VERSION ""

NS_ :

BS_:

BU_: Tester Charger TEL Display BMS VCU MotorController Front_BPS Rear_BPS Vehicle Tester Charger TEL Display BMS VCU MotorController Front_BPS Rear_BPS Vehicle

VAL_TABLE_ Brightness_Control 10 "100% Brightness" 9 "90% Brightness" 8 "80% Brightness" 7 "70% Brightness" 6 "60% Brightness" 5 "50% Brightness" 4 "40% Brightness" 3 "30% Brightness" 2 "20% Brightness" 1 "10% Brightness" 0 "100% Brightness" ;
VAL_TABLE_ VCU_Charge_Current_Lim_A 7 "FAULT_BIT_READ_SBS_CONFIG" 6 "FAULT_BIT_READ_CALIBRATION" 5 "FAULT_BIT_READ_POWER" 4 "FAULT_BIT_READ_FUEL_GAUGING" 3 "FAULT_BIT_READ_ADV_CHRG_ALGO" 2 "FAULT_BIT_READ_PERM_FAIL" 1 "FAULT_BIT_READ_SETTINGS" 0 "FAULT_BIT_READ_PROTECTION" ;
VAL_TABLE_ Hibernation 2 "Blink" 1 "Enabled" 0 "Disabled" ;
VAL_TABLE_ SpeedMode 3 "Rush" 2 "Ride" 1 "Eco" 0 "Default" ;
VAL_TABLE_ TripStatus 1 "Trip2" 0 "Trip1" ;
VAL_TABLE_ Charger_Status_ERR_NRML 1 "Error" 0 "Normal" ;
VAL_TABLE_ Charger_TX 1 "Disable" 0 "Enable" ;
VAL_TABLE_ Error_State 2 "Permanenet_Fault" 1 "Temporary_Fault" 0 "No Fault" ;
VAL_TABLE_ Kill_SwitchStatus 1 "kill Switch Off" 0 "Kill Switch On" ;
VAL_TABLE_ Switch_statius 1 "Pressed" 0 "Not  Pressed" ;
VAL_TABLE_ Throttle_Control 1 "VCU CAN Command throttle%" 0 "Motor Controller HW Throttle%" ;
VAL_TABLE_ DriveMode_Req 3 "Rush" 2 "Ride" 1 "Eco" 0 "Default" 7 "Reserved" 6 "Reserved" 5 "Reserved" 4 "Reserved" ;
VAL_TABLE_ Deratings 1 "Enabled" 0 "Disabled" ;
VAL_TABLE_ DriveMode_Ack 7 "Reserved" 6 "Reserved" 5 "Reserved" 4 "Reserved" 3 "Rush" 2 "Ride" 1 "Eco" 0 "Reserved" ;
VAL_TABLE_ OCD_Latch 1 "Lacth" 0 "Default" ;
VAL_TABLE_ Load_V_present 1 "DFET On" 0 "DFET Off" ;
VAL_TABLE_ KeyStatus_BMS 1 "Connected_vl" 0 "Not Connected_ep" ;
VAL_TABLE_ DFET_Status 1 "MDFET_ON" 0 "MDFET_OFF" ;
VAL_TABLE_ BMS_Fault_Status 1 "Error" 0 "Normal" ;
VAL_TABLE_ Battery_DFET_Temp_Warning 2 "FET_UNDER_TEMP" 1 "FET_OVER_TEMP" 0 "NO_FET_TEMP_FAULT" ;
VAL_TABLE_ Battery_DFET_TempFault 3 "Reserved" 2 "DFET Under Temperature" 1 "DFET Over Temperature" 0 "No Fault" ;
VAL_TABLE_ Battery_CFET_Temp_Fault 3 "Reserved" 2 "CFET Uder Temperature" 1 "CFET Over Temperature" 0 "No Fault" ;
VAL_TABLE_ CellVoltageFault 3 "Reserved" 2 "Cell Under Votage Fault" 1 "Cell Over Voltage Fault" 0 "No Fault" ;
VAL_TABLE_ Battery_Voltage_fault 3 "Reserved" 2 "Pack Under Voltage Fault" 1 "Pack Over Voltage Fault" 0 "No Fault" ;
VAL_TABLE_ Battery_Thermalrunaway_fault 1 "Fault" 0 "No Fault" ;
VAL_TABLE_ Battery_DischargeTempFault 4 "Charging Under Temperature" 3 "Discharging Under Temperature" 2 "Charging Over Temperature" 1 "Discharging Over Temperature" 0 "No Fault" ;
VAL_TABLE_ Reverse_Enable_Disable 1 "Disable" 0 "Enable" ;
VAL_TABLE_ Charger_LED_Color 3 "Reserved" 2 "Green" 1 "Red" 0 "Disable" ;
VAL_TABLE_ ChargerLEDBlink 15 "na" 14 "na" 13 "na" 12 "na" 11 "na" 10 "na" 9 "na" 8 "na" 7 "na" 6 "na" 5 "na" 4 "blink 4 times" 3 "blink 3 times" 2 "blink 2 times" 1 "blink 1 time" 0 "no blink" ;
VAL_TABLE_ SOH_estimation_flag 7 "NA" 6 "NA" 5 "NA" 4 "NA" 3 "Both flag on" 2 "SOH estimation flag on" 1 "SOH reset trigger on" 0 "Default" ;
VAL_TABLE_ Cell_Upnormal_Voltage 2 "UP_Normal_Min_Voltage_Fault" 1 "UP_Normal_Max_Voltage_Fault" 0 "NO_error" ;
VAL_TABLE_ BMS_State 6 "BMS_Calibration" 5 "BMS_Critical_Fault" 4 "BMS_Charging_Fault" 3 "BMS_Discharging_Fault" 2 "BMS_Charging" 1 "BMS_Discharging" 0 "Idle" ;
VAL_TABLE_ VCU_Trip_status 1 "Trip 2" 0 "Trip 1" ;
VAL_TABLE_ Rare_BPS_Timeout 1 "Rare_BPS_Timeout" 0 "No error" ;
VAL_TABLE_ Front_BPS_TimeOut 2 "reserved" 1 "Front_BPS_Timeout" 0 "No_error" ;
VAL_TABLE_ VehicleModeStatus 6 "Traction disable" 5 "Linphome mode while traction" 4 "Charge" 3 "Traction" 2 "Idle" 1 "Authentication" 0 "Lock" ;
VAL_TABLE_ BootStatus 1 "Boot_opean" 0 "Boot_locked" ;
VAL_TABLE_ ECUErrorCode 326 "Cell Under Voltage Fault" 325 "Cell Over Voltage Fault" 322 "BrakeLamp_Fault" 318 "BMS_CANMSG_Timeout" 315 "Battery_Thermal_Runaway_Fault" 314 "BatteryDisSortCircuitFault" 312 "Charging_under_temp" 310 "Discharging_under_temp" 309 " Charging_over_current_fault" 308 "Discharging_over_current_fault" 307 "Charging_over_temp" 306 "Discharging_over_temp" 305 "DFET under temperature" 304 "DFET over temperature" 303 "CFET under temperature" 302 "CFET over temperature" 301 "Fuse_Fault" 203 "BMS_SCD" 142 "Throttle_2_Low_Voltage" 140 "Motor_Control_Error" 139 "Application_parameters_Fault" 137 "Kill_switch_SRO" 136 "Max_speed_exceeded" 135 "Controller_logic_supply_error" 134 "Throttle channel mismatch " 133 "Motor Stalled" 132 "Throttle SRO" 131 "Contactor_Coil_Overcurrent" 130 "Parameter_Limitation" 129 "Throttle_2_High_Voltage" 128 "High Motor Temperature" 127 "High Controller Temperature" 126 "Corrupted_Position_Sensor_Cal" 125 "Corrupted_Persis_Para" 124 "Corrupted_Comm_Parameters" 123 "Corrupted_Throttle_Calibration" 122 "Corrupted V&I Sensor Calibration" 121 "Motor_Temperature_Sensor" 120 "Controller_Temperature_Sensor" 119 "Motor over temperature" 118 "Controller over temperature" 117 "Charging_Of_Capacitors_Failed" 116 "Throttle 1 Low Voltage" 115 "Throttle 1 High Voltage" 114 "Encoder_Fault" 113 "Throttle_Pedal_Cal_Error" 112 "Corrupted_Application_Parameters" 111 "Contactor_Welded" 110 "Contactor_Bridge_Fault" 109 "Over_Current" 108 "Current_Sensor_Fault" 107 "Sensor_Calibration_Error_V&I" 106 "12V_Failure" 105 "5V_Failure" 104 "Under_Voltage" 103 "Over_Voltage" 102 "Low_Battery_Voltage" 101 "High_Battery_Voltage" ;
VAL_TABLE_ SolenoidFeedbackStatus 1 "solenoid latched" 0 "solenoid unlatched" ;
VAL_TABLE_ RegenFlag 1 "Enable" 0 "Disable" ;
VAL_TABLE_ CalibrationDataSetNumber 4 "Cell 13,14 data" 3 "Cell 10,11,12 data" 2 "Cell 7,8,9 data" 1 "Cell 4,5,6 data" 0 "Cell 1,2,3 data" ;
VAL_TABLE_ CalibrationDescription 171 "Current Mode" 170 "Voltage Mode  " 34 "Current Calibration Third Point" 33 "Voltage Calibration Third Point" 18 "Current Calibration Second Point" 17 "Voltage Calibration Second Point" 2 "Current Calibration First Point" 1 "Voltage Calibration First Point" ;
VAL_TABLE_ CalibrationAckStatus 171 "Current Mode" 170 "Voltage Mode" 17 "Second Voltage point read" 3 "FinalCurrentPointReadCalibrated" 2 "Current point read" 1 "First Voltage point read" ;
VAL_TABLE_ AFESrecWriteStatus 1 "afe_srec written" 0 "afe_srec_not_written" ;
VAL_TABLE_ AFEDataFlashMemoryWriteFaultCode 7 " FAULT_BIT_READ_SBS_CONFIG" 6 "FAULT_BIT_READ_CALIBRATION" 5 "FAULT_BIT_READ_POWER" 4 "FAULT_BIT_READ_FUEL_GAUGING" 3 " FAULT_BIT_READ_ADV_CHRG_ALGO" 2 "FAULT_BIT_READ_PERM_FAIL" 1 "FAULT_BIT_READ_SETTINGS" 0 "FAULT_BIT_READ_PROTECTION" ;
VAL_TABLE_ I2c_Status 517 "STATUS_I2C_BUS_BUSY" 516 "STATUS_I2C_ABORTED" 515 "STATUS_I2C_ARBITRATION_LOST " 514 "STATUS_I2C_RX_OVERRUN " 513 "STATUS_I2C_TX_UNDERRUN" 512 "STATUS_I2C_RECEIVED_NACK " ;
VAL_TABLE_ SystemDiagInitFaultCode 30 "FaultBitReadAFEHistoryFaultData" 29 "FAULTBIT_READ_AFE_LIFE_TIME_DATA" 28 "FAULT_BIT_INT_FLASH_WRITE_FAILED" 27 "FAULT_BIT_INT_FLASH_READ_FAILED" 26 "AULT_BIT_ADC_READ" 25 "FAULT_BIT_AFE_READ " 24 "FAULT_BIT_POST_OS_INIT_FAILED" 23 "FAULT_BIT_OS_CREATE_INTRPTS" 22 "FAULT_BIT_OS_CREATE_TASK" 21 "FAULT_BIT_OS_CREATE_QUEUE" 20 "FAULT_BIT_OS_CREATE_SEMPR" 19 "FAULT_BIT_CAN_TX" 18 "FAULT_BIT_INTERNAL_FLASH_INIT" 17 "FAULT_BIT_I2C_CRC_ERROR" 16 "FAULT_BIT_I2C_RX_ERROR" 15 "FAULT_BIT_I2C_TX_ERROR" 14 "FAULT_BIT_I2C_INIT" 13 "FAULT_BIT_ADC_INIT" 12 "FAULT_BIT_TIMER_FTM1" 11 "FAULT_BIT_TIMER_FTM0" 10 "FAULT_BIT_CAN_INIT_1" 9 "FAULT_BIT_GPIO_INIT" 8 "FAULT_BIT_CLOCK_UPDATE" 7 "FAULT_BIT_BOOT_CLOCK_INIT" 6 "FAULT_BIT_RESET_SOFT" 5 "FAULT_BIT_RESET_NRST_EXT" 4 "FAULT_BIT_RESET_ACK_ERR" 3 "FAULT_BIT_RESET_LV_DETECT" 2 "FAULT_BIT_RESET_SJTAG" 1 "FAULT_BIT_RESET_POWER_ON" 0 "FAULT_BIT_RESET_WDG" ;
VAL_TABLE_ BatteryAFETempWarning 4 "CHARGING_UNDER_TEMP_FAULT" 3 "DISCHARGING_UNDER_TEMPE_FAULT" 2 "CHARGING_OVER_TEMP_FAULT" 1 "DISCHARGING_OVER_TEMPE_FAULT" 0 "NO_TEMP_FAULT" ;
VAL_TABLE_ BatteryMDFETTempWarning 2 "FET_UNDER_TEMP" 1 "FET_OVER_TEMP" 0 "NO_FET_TEMP_FAULT" ;
VAL_TABLE_ BatteryCellVoltageWarning 2 "UNDER_VOLTAGE_FAULT" 1 "OVER_VOLTAGE_FAULT" 0 "NO_VOLTAGE_FAULT" ;
VAL_TABLE_ BatteryCFETTempWarning 2 "CHARG_UNDER_TEMP_FAULT" 1 "CHARG_OVER_TEMP_FAULT" 0 "NO_CHG_TEMP_FAULT" ;
VAL_TABLE_ BatteryTempWarning 4 "CHARGING_UNDER_TEMP_FAULT" 3 "DISCHARGING_UNDER_TEMPE_FAULT" 2 "CHARGING_OVER_TEMP_FAULT" 1 "DISCHARGING_OVER_TEMPE_FAULT" 0 "NO_TEMP_FAULT" ;
VAL_TABLE_ BatteryCurrentWarning 3 "RESERVED" 2 " CHARGING_OVER_CURRENT_FAULT" 1 "DISCHARGING_OVER_CURRENT_FAULT" 0 "NO_CURRENT_FAULT" ;
VAL_TABLE_ ParkArrowBlink 3 "Top and Bottom Arrow Blink" 2 "Top Arrow Blink" 1 "Bottom Arrow Blink" 0 "No Blink" ;
VAL_TABLE_ On_Off 1 "ON" 0 "OFF" ;
VAL_TABLE_ LED_Color 3 "Reserved" 2 "Green" 1 "Red" 0 "Disable" ;
VAL_TABLE_ BatteryChargingTempFault 4 "Reserved" 3 "Reserved" 2 "Charging Under Temperature" 1 "Charging Over Temperature" 0 "No Fault" ;
VAL_TABLE_ BatteryFull 1 "Battery Full" 0 "Default" ;
VAL_TABLE_ Latch 1 "Latch" 0 "Default" ;
VAL_TABLE_ Gauge_TemperatureFault 3 "Reserved" 2 "Gauge UT Fault" 1 "Gauge OT Fault" 0 "Gauge Temperature Normal" ;
VAL_TABLE_ Auth_Fault 1 "Auth Fault" 0 "No Auth Fault" ;
VAL_TABLE_ Fuse 1 "Fuse Blown" 0 "Normal" ;
VAL_TABLE_ Reset_Display 7 "Reserved" 6 "Reserved" 5 "Reserved" 4 "Reserved" 3 "Clear Service Icon" 2 "Reset Trip 2" 1 "Reset Trip1" 0 "Default" ;
VAL_TABLE_ CFET_Status 1 "CFET On" 0 "CFET Off" ;
VAL_TABLE_ Charger_Enable 1 "Disable" 0 "Enable" ;
VAL_TABLE_ DrivenMode 7 "Reserved" 6 "Reserved" 5 "Reserved" 4 "Reserved" 3 "Reserved" 2 "Rush" 1 "Sport" 0 "Ride" ;
VAL_TABLE_ Park_Mode_Direction 1 "Forward" 0 "Reverse" ;
VAL_TABLE_ Park_Mode_Enable 1 "Park Enabled" 0 "Park Disabled" ;
VAL_TABLE_ Version_Req 1 "Update Version" 0 "Default" ;
VAL_TABLE_ VehicleMode 9 "Reserved" 8 "Reserved" 7 "Reserved" 6 "Hibernation" 5 "Cloud Update Mode" 4 "Charging" 3 "Reverse" 2 "Forward" 1 "Idle" 0 "Sleep/Lock" ;
VAL_TABLE_ FET_Fault 3 "Reserved" 2 "Reserved" 1 "Over Temperature " 0 "No Fault" ;
VAL_TABLE_ Precharging_Status 3 "Precharging Failed" 2 "Precharging Successful" 1 "Precharging In-progress" 0 "Default" ;
VAL_TABLE_ Drive_Manoeuvre 4 "Acceleration Backward" 3 "Direction Transition" 2 "Service Braking " 1 "Neutral braking" 0 "Accelartion Forward  " ;
VAL_TABLE_ Motor_ErrorCodes 94 "Kill switch Off" 93 "Kill switch SRO" 83 "Motor stalled " 82 "Throttle SRO" 52 "High motor temperature " 51 "High controller temperature " 97 "Motor control error " 96 "Application parameters fault" 92 "Max. speed exceeded " 90 "Controller logicsupply error " 85 "Throttle channel mismatch " 66 "Contactor coil overcurrent" 56 "Parameter limitation" 54 "Throttle 1 Low Voltage" 53 "Throttle 2 High Voltage" 49 "Corrupted positionsensor cal" 48 "Corrupted Persis Para" 47 "Corrupted Comm parameters \r" 46 "Corrupted throttle calibration" 45 "Corrupted V&I sensor calibration" 44 "Motor temperature sensor" 43 "Controller temperature sensor" 42 "Motor over temperature" 36 "Charging of capacitors failed " 34 "Throttle 1 Low Voltage" 32 "Encoder Fault" 41 "Controller over temperature" 33 "Throttle 1 High Voltage" 31 "Throttle Pedal Cal Error" 26 "Corrupted Application Parameters" 25 "Contactor  Welded" 24 "Contactor Bridge Fault" 21 "Over Current" 18 "Current Sensor Fault" 17 "Sensor Calibration Error V&I" 16 "12V Failure" 15 "5V Failure" 14 "Under Voltage V<32" 13 "Over Voltage V>62" 12 "Low Battery Voltage V<28" 11 "High Battery Voltage V>100" ;
VAL_TABLE_ Am_Pm 1 "pm" 0 "am" ;
VAL_TABLE_ Blink 1 "Blinking" 0 "No Blinking" ;
VAL_TABLE_ Trip 1 "Trip 2" 0 "Trip 1" ;
VAL_TABLE_ Enable_Disable 1 "Enabled" 0 "Disabled" ;
VAL_TABLE_ Direction 3 "Reserved" 2 "Reverse" 1 "Forward" 0 "Neutral" ;
VAL_TABLE_ KillSwitch 1 "Kill Switch Off" 0 "Kill Switch On" ;
VAL_TABLE_ PowerStage 3 "Not Used" 2 "On" 1 "Active Short" 0 "Off" ;
VAL_TABLE_ MotorMode 7 "Reserved" 6 "Reserved" 5 "Reserved" 4 "Reserved" 3 "Rush" 2 "Ride" 1 "Eco" 0 "Reserved" ;
VAL_TABLE_ BrakeStatus 1 "Pressed" 0 "Not Pressed" ;
VAL_TABLE_ SideStandStatus 1 "Up" 0 "Down" ;
VAL_TABLE_ ServiceIndication 1 "Enable" 0 "Disable" ;
VAL_TABLE_ ChargePlugStatus 1 "Connected" 0 "Not Connected" ;
VAL_TABLE_ RegenStatus 1 "Enabled" 0 "Disabled" ;
VAL_TABLE_ VCU_DisplayMode 9 "Reserved" 8 "Reserved" 7 "Reserved" 6 "Factory Mode" 5 "Charging" 4 "Park Forward" 3 "Park Reverse" 2 "Forward" 1 "Idle" 0 "Sleep" ;
VAL_TABLE_ Green_Red 3 "Green&Red" 2 "Red" 1 "Green" 0 "Default" ;
VAL_TABLE_ CurrentFaults 3 "Reserved" 2 "Charging Over Current Fault" 1 "Discharging Over Current Fault" 0 "No Fault" ;
VAL_TABLE_ VoltageFaults 3 "Reserved " 2 "Under Voltage Fault" 1 "Over Voltage Fault" 0 "No Fault" ;
VAL_TABLE_ BatteryDischargingTempFault 4 "Reserved" 3 "Reserved" 2 "Discharging Under Temperature" 1 "Discharging Over Temperature" 0 "No Fault" ;
VAL_TABLE_ Fault 1 "Fault" 0 "No Fault" ;
VAL_TABLE_ Authentication 3 "Fail" 2 "Pass" 1 "InProgress" 0 "Default" ;
VAL_TABLE_ BalancingStatus 1 "Balancing" 0 "Not Balancing" ;
VAL_TABLE_ BMS_Status 10 "Reserved_l" 9 "Reserved_v" 8 "Reserved_p" 7 "Charge Recovery Fault" 6 "Discharge Recovery Fault" 5 "Critical Fault" 4 "Hibernate" 3 "Charging" 2 "Discharging" 1 "Precharging" 0 "Sleep_e" ;
VAL_TABLE_ charger_status_msg 1 "Error" 0 "Normal" ;
VAL_TABLE_ SECURITY_Mode_OP_sts 3 "Sealed" 2 "Unsealed" 1 "Full_Access" 0 "Reserved" ;
VAL_TABLE_ Error_Code_BT_Sts 7 "Unknown_Error" 6 "Bad_Size" 5 "Overflow/UnderFlow" 4 "AccessDenied" 3 "unsupported_Command" 2 "Reserved_Command" 1 "Busy" 0 "OK" ;
VAL_TABLE_ Charger_Status 1 "ERROR" 0 "NORMAL" ;
VAL_TABLE_ FLT_Cell_Voltage_Deep_Discharge 1 "FAULT" 0 "NO_FAULT" ;
VAL_TABLE_ FLT_Charger_CAN_Timeout_BMS_val 1 "FAULT" 0 "NO_FAULT" ;
VAL_TABLE_ FLT_Motor_CAN_Timeout_BMS_val 1 "FAULT" 0 "NO_FAULT" ;
VAL_TABLE_ FLT_Cell_temp_imbalance_val 1 "FAULT" 0 "NO_FAULT" ;
VAL_TABLE_ FLT_vcc_aux_fail_val 1 "FAULT" 0 "NO_FAULT" ;
VAL_TABLE_ FLT_uvlo_val 1 "FAULT" 0 "NO_FAULT" ;
VAL_TABLE_ FLT_Precharge_Permanent_Fail_Sta 1 "FAULT" 0 "NO_FAULT" ;
VAL_TABLE_ FLT_Mosfet_Failure_val 1 "FAULT" 0 "NO_FAULT" ;
VAL_TABLE_ WAR_BMS_Thermal_Deration_Active 1 "ACTIVE" 0 "NOT_ACTIVE" ;
VAL_TABLE_ WAR_BMS_CAN_TX_Warning_Error_val 1 "ERROR" 0 "NO_ERROR" ;
VAL_TABLE_ WAR_BMS_CAN_RX_Warning_Error_val 1 "ERROR" 0 "NO_ERROR" ;
VAL_TABLE_ FLT_System_Diag_Init_Fault_Code 30 "FLT_RD_AFE_HISTORY_FAULT_DATA" 29 "FLT_RD_AFE_LIFE_TIME_DATA" 28 "FLT_INT_FLASH_WRITE_FAILED" 27 "FLT_INT_FLASH_RD_FAILED" 26 "FLT_ADC_READ" 25 "FLT_AFE_READ" 24 "FLT_POST_OS_INIT_FAILED" 23 "FLT_OS_CREATE_INTRPTS" 22 "FLT_OS_CREATE_TASK" 21 "FLT_OS_CREATE_QUEUE" 20 "FLT_OS_CREATE_SEMPR" 19 "FLT_CAN_TX" 18 "FLT_INTERNAL_FLASH_INIT" 17 "FLT_I2C_CRC_ERROR" 16 "FLT_I2C_RX_ERROR" 15 "FLT_I2C_TX_ERROR" 14 "FLT_I2C_INIT" 13 "FLT_ADC_INIT" 12 "FLT_TIMER_FTM1" 11 "FLT_TIMER_FTM0" 10 "FLT_CAN_INIT_1" 9 "FLT_GPIO_INIT" 8 "FLT_CLOCK_UPDATE" 7 "FLT_BOOT_CLOCK_INIT" 6 "FLT_RESET_SOFT" 5 "FLT_RESET_NRST_EXT" 4 "FLT_RESET_ACK_ERR" 3 "FLT_RESET_LV_DETECT" 2 "FLT_RESET_SJTAG" 1 "FLT_RESET_POWER_ON" 0 "FLT_RESET_WDG" ;
VAL_TABLE_ STA_AutoHybernation_TimeOut_Stat 1 "INITIATED" 0 "NOT_INITIATED" ;
VAL_TABLE_ STA_BMS_MCU_SCD_Trigger_val 1 "FAULT" 0 "NO_FAULT" ;
VAL_TABLE_ STA_BMS_MCU_5V_PG_val 1 "ENABLE" 0 "DISABLE" ;
VAL_TABLE_ STA_MCU_14V_PG_val 1 "ENABLE" 0 "DISABLE" ;
VAL_TABLE_ STA_PFET_STS_val 1 "ON" 0 "OFF" ;
VAL_TABLE_ FLT_BattDisch_ShortCircuit_val 1 "FAULT" 0 "NO_FAULT" ;
VAL_TABLE_ WAR_cell_voltage_imbalance_val 1 "IMBALANCED" 0 "BALANCED" ;
VAL_TABLE_ WAR_cell_temperature_imbalance_v 1 "IMBALANCED" 0 "BALANCED" ;
VAL_TABLE_ FLT_CAN_H_L_Short_Val 1 "FAULT" 0 "NO_FAULT" ;
VAL_TABLE_ FLT_Indicator_One_FaultFlag_Val 1 "FAULT" 0 "NO_FAULT" ;
VAL_TABLE_ FLT_Low_SOC_RTD_CutOff_Val 1 "FAULT" 0 "NO_FAULT" ;
VAL_TABLE_ FLT_Indicator_Two_FaultFlag_Val 1 "FAULT" 0 "NO_FAULT" ;
VAL_TABLE_ Batt_Charger_Plugged_In_Val 1 "PLUGGED" 0 "UNPLUGGED" ;
VAL_TABLE_ STA_Hybernation_Seq_Enable_Val 1 "ENABLE" 0 "DISABLE" ;
VAL_TABLE_ STA_Service_Mode_Active_Val 1 "ENABLE" 0 "DISABLE" ;
VAL_TABLE_ STA_Soleoid_attempt_status_Val 2 "UNLATCHING" 1 "LATCHING" 0 "NO_ACTION" ;
VAL_TABLE_ STA_Authentication_status_Val 1 "PASSED" 0 "FAILED" ;
VAL_TABLE_ STA_DCDC_Enable_statusVal 1 "ENABLE" 0 "DISABLE" ;
VAL_TABLE_ Chg_Plug_Blink_Enable_Val 1 "BLINKING" 0 "NO_BLINKING" ;
VAL_TABLE_ Side_stand_Blink_Val 1 "BLINKING" 0 "NO_BLINKING" ;

BO_ 618 Charger_Mains: 8 Charger
 SG_ Main_RMS_Voltage : 0|16@1+ (0.01,0) [0|655.35] "" Vector__XXX

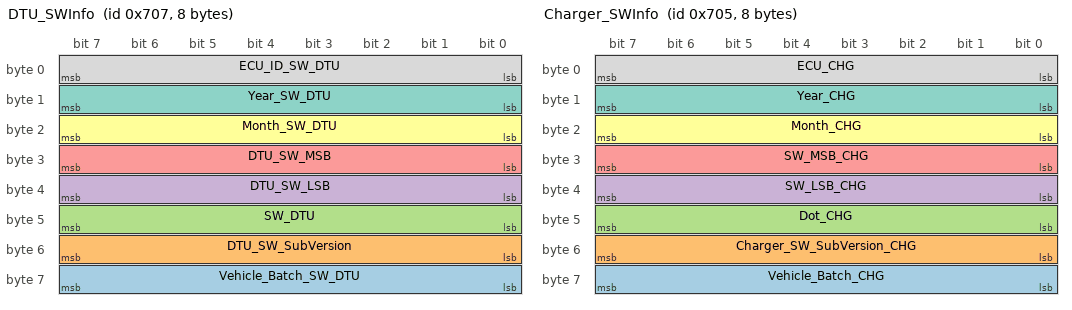
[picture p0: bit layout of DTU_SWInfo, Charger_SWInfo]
BO_ 1799 DTU_SWInfo: 8 Vector__XXX
 SG_ Vehicle_Batch_SW_DTU : 56|8@1+ (1,0) [0|255] "" Vector__XXX
 SG_ DTU_SW_SubVersion : 48|8@1+ (1,0) [0|255] "" Vector__XXX
 SG_ SW_DTU : 40|8@1+ (1,0) [0|255] "" Vector__XXX
 SG_ DTU_SW_LSB : 32|8@1+ (1,0) [0|255] "" Vector__XXX
 SG_ DTU_SW_MSB : 24|8@1+ (1,0) [0|255] "" Vector__XXX
 SG_ Month_SW_DTU : 16|8@1+ (1,0) [0|255] "" Vector__XXX
 SG_ Year_SW_DTU : 8|8@1+ (1,0) [0|255] "" Vector__XXX
 SG_ ECU_ID_SW_DTU : 0|8@1+ (1,0) [0|255] "" Vector__XXX

BO_ 628 Battery_Deration_Model_Output1: 8 BMS
 SG_ Thermal_Derated_Current : 16|16@1+ (1,0) [0|65535] ""  Tester

BO_ 615 KalmanFilter_SOC: 8 BMS
 SG_ Kalman_Filter_SOC : 48|16@1+ (0.01,0) [0|655.35] ""  VCU,Tester,TEL
 SG_ Kalman_Coulomb_SOC : 16|16@1+ (0.01,0) [0|655.35] ""  VCU,Tester,TEL

BO_ 614 CellVolt_13_14_FET_volt_sense: 8 BMS
 SG_ Battery_Pack_Hw_Version_Voltage : 48|16@1+ (0.01,0) [0|655.35] "" Vector__XXX
 SG_ CellV14 : 16|16@1+ (0.001,0) [0|655.35] "V" Vector__XXX
 SG_ CellV13 : 0|16@1+ (0.001,0) [0|65.535] "V" Vector__XXX
 SG_ FET_Out : 32|16@1+ (0.01,0) [0|65.535] "V"  VCU,TEL

BO_ 613 CellV_9_10_11_12: 8 BMS
 SG_ CellV12 : 48|16@1+ (0.001,0) [0|65.535] ""  VCU,TEL
 SG_ CellV11 : 32|16@1+ (0.001,0) [0|65.535] ""  VCU,TEL
 SG_ CellV10 : 16|16@1+ (0.001,0) [0|65.535] ""  VCU,TEL
 SG_ CellV9 : 0|16@1+ (0.001,0) [0|65.535] ""  VCU,TEL

BO_ 612 CellVolt_5_6_7_8: 8 BMS
 SG_ CellV8 : 48|16@1+ (0.001,0) [0|65.535] ""  VCU,TEL
 SG_ CellV7 : 32|16@1+ (0.001,0) [0|65.535] "V"  VCU,TEL
 SG_ CellV6 : 16|16@1+ (0.001,0) [0|65.535] ""  VCU,TEL
 SG_ CellV5 : 0|16@1+ (0.001,0) [0|65.535] ""  VCU,TEL

BO_ 611 CellVolt_1_2_3_4: 8 BMS
 SG_ CellV4 : 48|16@1+ (0.001,0) [0|65.535] ""  VCU,TEL
 SG_ CellV3 : 32|16@1+ (0.001,0) [0|65.535] ""  VCU,TEL
 SG_ CellV2 : 16|16@1+ (0.001,0) [0|65.535] ""  VCU,TEL
 SG_ CellV1 : 0|16@1+ (0.001,0) [0|65.535] "V"  VCU,TEL

BO_ 587 Rear_Bps: 8 VCU
 SG_ Rear_Bps_Value : 8|32@1+ (0.01,0) [0|42949672.95] ""  Tester
 SG_ Rear_Bps_ID : 0|8@1+ (1,0) [0|255] ""  Tester

BO_ 586 Front_Bps: 8 VCU
 SG_ Front_BPS_Value : 8|32@1+ (0.01,0) [0|42949672.95] ""  Tester
 SG_ Front_Bps_ID : 0|8@1+ (1,0) [0|255] ""  Tester

BO_ 584 Motor_Odometer: 8 MotorController
 SG_ Motor_ODO_MCU : 0|24@1+ (0.1,0) [0|1677721.5] "Km"  VCU

BO_ 1797 Charger_SWInfo: 8 Charger
 SG_ Vehicle_Batch_CHG : 56|8@1+ (1,0) [0|255] ""  TEL
 SG_ Charger_SW_SubVersion_CHG : 48|8@1+ (1,0) [0|255] ""  TEL
 SG_ Dot_CHG : 40|8@1+ (1,0) [0|255] ""  TEL
 SG_ SW_LSB_CHG : 32|8@1+ (1,0) [0|255] ""  TEL
 SG_ SW_MSB_CHG : 24|8@1+ (1,0) [0|255] ""  TEL
 SG_ Month_CHG : 16|8@1+ (1,0) [0|255] ""  TEL
 SG_ Year_CHG : 8|8@1+ (1,0) [0|255] ""  TEL
 SG_ ECU_CHG : 0|8@1+ (1,0) [0|255] ""  TEL

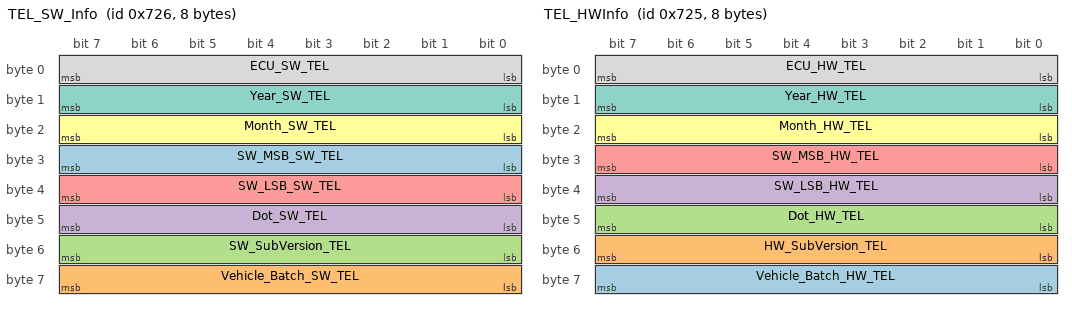
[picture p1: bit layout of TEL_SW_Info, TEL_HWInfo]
BO_ 1830 TEL_SW_Info: 8 TEL
 SG_ SW_MSB_SW_TEL : 24|8@1+ (1,0) [-128|127] ""  VCU
 SG_ Vehicle_Batch_SW_TEL : 56|8@1+ (1,0) [0|255] ""  VCU
 SG_ SW_SubVersion_TEL : 48|8@1+ (1,0) [0|255] ""  VCU
 SG_ Dot_SW_TEL : 40|8@1+ (1,0) [0|255] ""  VCU
 SG_ SW_LSB_SW_TEL : 32|8@1+ (1,0) [0|255] ""  VCU
 SG_ Month_SW_TEL : 16|8@1+ (1,0) [0|255] ""  VCU
 SG_ Year_SW_TEL : 8|8@1+ (1,0) [0|255] ""  VCU
 SG_ ECU_SW_TEL : 0|8@1+ (1,0) [0|255] ""  VCU

BO_ 1829 TEL_HWInfo: 8 TEL
 SG_ Vehicle_Batch_HW_TEL : 56|8@1+ (1,0) [0|255] ""  VCU
 SG_ HW_SubVersion_TEL : 48|8@1+ (1,0) [0|255] ""  VCU
 SG_ Dot_HW_TEL : 40|8@1+ (1,0) [0|255] ""  VCU
 SG_ SW_LSB_HW_TEL : 32|8@1+ (1,0) [0|255] ""  VCU
 SG_ SW_MSB_HW_TEL : 24|8@1+ (1,0) [0|255] ""  VCU
 SG_ Month_HW_TEL : 16|8@1+ (1,0) [0|255] ""  VCU
 SG_ Year_HW_TEL : 8|8@1+ (1,0) [0|255] ""  VCU
 SG_ ECU_HW_TEL : 0|8@1+ (1,0) [0|255] ""  VCU

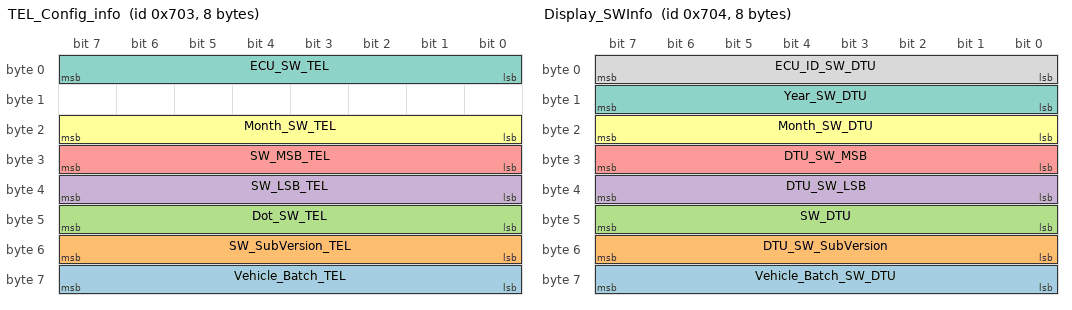
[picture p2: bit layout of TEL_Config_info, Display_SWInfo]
BO_ 1795 TEL_Config_info: 8 TEL
 SG_ Vehicle_Batch_TEL : 56|8@1+ (1,0) [0|255] ""  TEL
 SG_ SW_SubVersion_TEL : 48|8@1+ (1,0) [0|255] ""  TEL
 SG_ Dot_SW_TEL : 40|8@1+ (1,0) [0|255] ""  TEL
 SG_ SW_LSB_TEL : 32|8@1+ (1,0) [0|255] ""  TEL
 SG_ SW_MSB_TEL : 24|8@1+ (1,0) [0|255] ""  TEL
 SG_ Month_SW_TEL : 16|8@1+ (1,0) [0|255] ""  TEL
 SG_ ECU_SW_TEL : 0|8@1+ (1,0) [0|255] ""  TEL

BO_ 1796 Display_SWInfo: 8 Display
 SG_ Vehicle_Batch_SW_DTU : 56|8@1+ (1,0) [0|255] ""  TEL
 SG_ DTU_SW_SubVersion : 48|8@1+ (1,0) [0|255] ""  TEL
 SG_ SW_DTU : 40|8@1+ (1,0) [0|255] ""  TEL
 SG_ DTU_SW_LSB : 32|8@1+ (1,0) [0|255] ""  TEL
 SG_ DTU_SW_MSB : 24|8@1+ (1,0) [0|255] ""  TEL
 SG_ Month_SW_DTU : 16|8@1+ (1,0) [0|255] ""  TEL
 SG_ Year_SW_DTU : 8|8@1+ (1,0) [0|255] ""  TEL
 SG_ ECU_ID_SW_DTU : 0|8@1+ (1,0) [0|255] ""  TEL

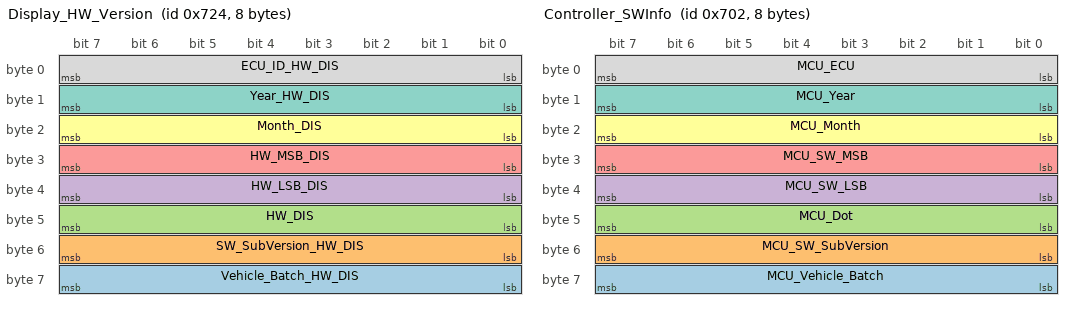
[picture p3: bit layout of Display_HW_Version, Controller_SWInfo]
BO_ 1828 Display_HW_Version: 8 Display
 SG_ Vehicle_Batch_HW_DIS : 56|8@1+ (1,0) [0|255] ""  VCU
 SG_ SW_SubVersion_HW_DIS : 48|8@1+ (1,0) [0|255] ""  VCU
 SG_ HW_DIS : 40|8@1+ (1,0) [0|255] ""  VCU
 SG_ HW_LSB_DIS : 32|8@1+ (1,0) [0|255] ""  VCU
 SG_ HW_MSB_DIS : 24|8@1+ (1,0) [0|255] ""  VCU
 SG_ Month_DIS : 16|8@1+ (1,0) [0|255] ""  VCU
 SG_ Year_HW_DIS : 8|8@1+ (1,0) [0|255] ""  VCU
 SG_ ECU_ID_HW_DIS : 0|8@1+ (1,0) [0|255] ""  VCU

BO_ 1794 Controller_SWInfo: 8 MotorController
 SG_ MCU_Vehicle_Batch : 56|8@1+ (1,0) [0|255] ""  TEL
 SG_ MCU_SW_SubVersion : 48|8@1+ (1,0) [0|255] ""  TEL
 SG_ MCU_Dot : 40|8@1+ (1,0) [0|255] ""  TEL
 SG_ MCU_SW_LSB : 32|8@1+ (1,0) [0|255] ""  TEL
 SG_ MCU_SW_MSB : 24|8@1+ (1,0) [0|255] ""  TEL
 SG_ MCU_Month : 16|8@1+ (1,0) [0|255] ""  TEL
 SG_ MCU_Year : 8|8@1+ (1,0) [0|255] ""  TEL
 SG_ MCU_ECU : 0|8@1+ (1,0) [0|255] ""  TEL

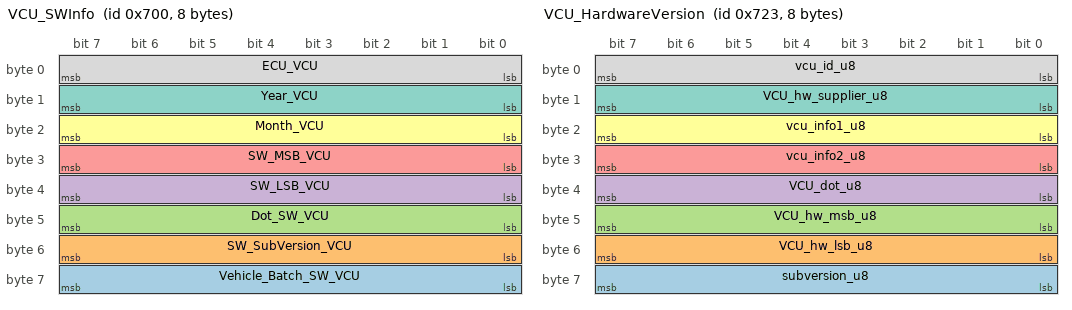
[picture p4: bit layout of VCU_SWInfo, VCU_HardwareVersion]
BO_ 1792 VCU_SWInfo: 8 VCU
 SG_ Vehicle_Batch_SW_VCU : 56|8@1+ (1,0) [0|255] ""  TEL
 SG_ SW_SubVersion_VCU : 48|8@1+ (1,0) [0|255] ""  TEL
 SG_ Dot_SW_VCU : 40|8@1+ (1,0) [0|255] ""  TEL
 SG_ SW_LSB_VCU : 32|8@1+ (1,0) [0|255] ""  TEL
 SG_ SW_MSB_VCU : 24|8@1+ (1,0) [0|255] ""  TEL
 SG_ Month_VCU : 16|8@1+ (1,0) [0|255] ""  TEL
 SG_ Year_VCU : 8|8@1+ (1,0) [0|255] ""  TEL
 SG_ ECU_VCU : 0|8@1+ (1,0) [0|255] ""  TEL

BO_ 1827 VCU_HardwareVersion: 8 VCU
 SG_ subversion_u8 : 56|8@1+ (1,0) [0|255] ""  TEL
 SG_ VCU_hw_lsb_u8 : 48|8@1+ (1,0) [0|255] ""  TEL
 SG_ VCU_hw_msb_u8 : 40|8@1+ (1,0) [0|255] ""  TEL
 SG_ VCU_dot_u8 : 32|8@1+ (1,0) [0|255] ""  TEL
 SG_ vcu_info2_u8 : 24|8@1+ (1,0) [0|255] ""  TEL
 SG_ vcu_info1_u8 : 16|8@1+ (1,0) [0|255] ""  TEL
 SG_ VCU_hw_supplier_u8 : 8|8@1+ (1,0) [0|255] ""  TEL
 SG_ vcu_id_u8 : 0|8@1+ (1,0) [0|255] ""  TEL

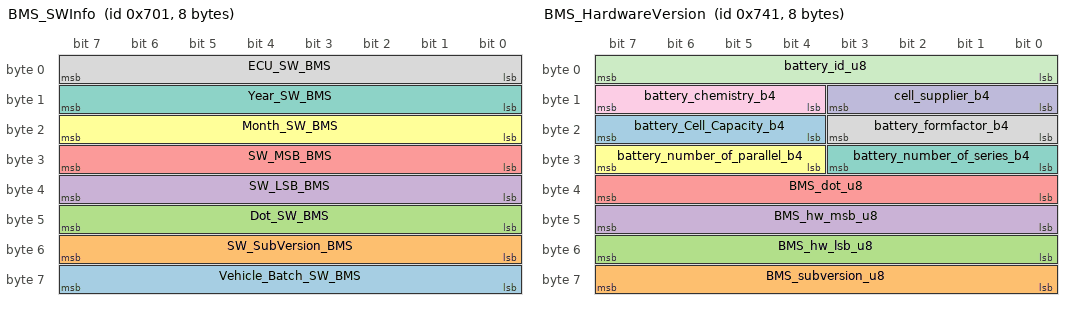
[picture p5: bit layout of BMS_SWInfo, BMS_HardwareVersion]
BO_ 1793 BMS_SWInfo: 8 BMS
 SG_ Vehicle_Batch_SW_BMS : 56|8@1+ (1,0) [0|255] ""  TEL
 SG_ SW_SubVersion_BMS : 48|8@1+ (1,0) [0|255] ""  TEL
 SG_ Dot_SW_BMS : 40|8@1+ (1,0) [0|255] ""  TEL
 SG_ SW_LSB_BMS : 32|8@1+ (1,0) [0|255] ""  TEL
 SG_ SW_MSB_BMS : 24|8@1+ (1,0) [0|255] ""  TEL
 SG_ Month_SW_BMS : 16|8@1+ (1,0) [0|255] ""  TEL
 SG_ Year_SW_BMS : 8|8@1+ (1,0) [0|255] ""  TEL
 SG_ ECU_SW_BMS : 0|8@1+ (1,0) [0|255] ""  TEL

BO_ 1857 BMS_HardwareVersion: 8 BMS
 SG_ battery_Cell_Capacity_b4 : 20|4@1+ (1,0) [0|15] "" Vector__XXX
 SG_ BMS_subversion_u8 : 56|8@1+ (1,0) [0|255] ""  TEL
 SG_ BMS_hw_lsb_u8 : 48|8@1+ (1,0) [0|255] ""  TEL
 SG_ BMS_hw_msb_u8 : 40|8@1+ (1,0) [0|255] ""  TEL
 SG_ BMS_dot_u8 : 32|8@1+ (1,0) [0|255] ""  TEL
 SG_ battery_number_of_parallel_b4 : 28|4@1+ (1,0) [0|15] ""  TEL
 SG_ battery_number_of_series_b4 : 24|4@1+ (1,0) [0|15] ""  TEL
 SG_ battery_formfactor_b4 : 16|4@1+ (1,0) [0|15] ""  TEL
 SG_ battery_chemistry_b4 : 12|4@1+ (1,0) [0|15] ""  TEL
 SG_ cell_supplier_b4 : 8|4@1- (1,0) [-8|7] ""  TEL
 SG_ battery_id_u8 : 0|8@1+ (1,0) [0|255] ""  TEL

BO_ 1638 Version_Req: 8 VCU
 SG_ Version_Request : 0|1@1+ (1,0) [0|1] ""  VCU,TEL,MotorController,Display,Charger,BMS

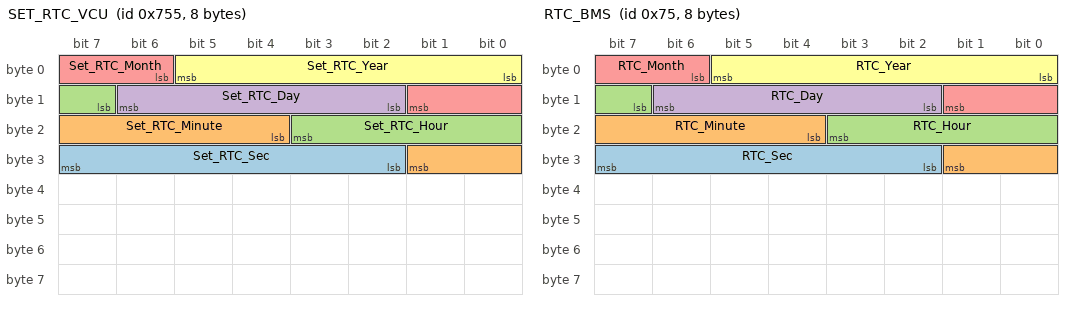
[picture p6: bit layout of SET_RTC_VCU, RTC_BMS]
BO_ 1877 SET_RTC_VCU: 8 Tester
 SG_ Set_RTC_Sec : 26|6@1+ (1,0) [0|63] ""  TEL,VCU
 SG_ Set_RTC_Minute : 20|6@1+ (1,0) [0|63] ""  TEL,VCU
 SG_ Set_RTC_Hour : 15|5@1+ (1,0) [0|31] ""  TEL,VCU
 SG_ Set_RTC_Day : 10|5@1+ (1,0) [0|31] ""  TEL,VCU
 SG_ Set_RTC_Month : 6|4@1+ (1,0) [0|15] ""  TEL,VCU
 SG_ Set_RTC_Year : 0|6@1+ (1,0) [0|63] ""  TEL,VCU

BO_ 117 RTC_BMS: 8 BMS
 SG_ RTC_Sec : 26|6@1+ (1,0) [0|63] ""  VCU
 SG_ RTC_Minute : 20|6@1+ (1,0) [0|63] ""  VCU
 SG_ RTC_Hour : 15|5@1+ (1,0) [0|31] ""  VCU
 SG_ RTC_Day : 10|5@1+ (1,0) [0|31] ""  VCU
 SG_ RTC_Month : 6|4@1+ (1,0) [0|15] ""  VCU
 SG_ RTC_Year : 0|6@1+ (1,0) [0|63] ""  VCU

BO_ 610 Battery_FET_Temp: 8 BMS
 SG_ AFE_Temperature : 0|16@1- (0.1,0) [-327.68|327.67] "" Vector__XXX
 SG_ FET2_Temperature : 32|16@1- (0.01,0) [-327.68|327.67] "degC"  VCU,TEL
 SG_ FET1_Temperature : 16|16@1- (0.01,0) [-327.68|327.67] "degC"  VCU,TEL

BO_ 609 Battery_Temperature: 8 BMS
 SG_ Pack_Ts4 : 48|16@1- (0.01,0) [-327.68|327.67] "degC"  VCU,TEL
 SG_ Pack_Ts3 : 32|16@1- (0.01,0) [-327.68|327.67] "degC"  VCU,TEL
 SG_ Pack_Ts2 : 16|16@1- (0.01,0) [-3276.8|3276.7] "degC"  VCU,TEL
 SG_ Pack_Ts1 : 0|16@1- (0.01,0) [-327.68|327.67] "degC"  VCU,TEL

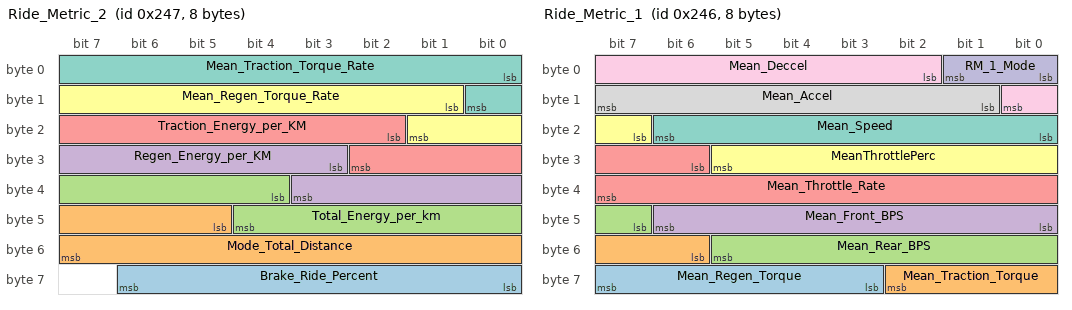
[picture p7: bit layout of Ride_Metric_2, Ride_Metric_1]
BO_ 583 Ride_Metric_2: 8 VCU
 SG_ Brake_Ride_Percent : 56|7@1+ (1,0) [0|127] ""  TEL
 SG_ Mode_Total_Distance : 45|11@1+ (0.1,0) [0|204.7] ""  TEL
 SG_ Total_Energy_per_km : 36|9@1+ (0.1,0) [0|51.1] ""  TEL
 SG_ Regen_Energy_per_KM : 27|9@1+ (0.1,0) [0|51.1] ""  TEL
 SG_ Traction_Energy_per_KM : 18|9@1+ (0.1,0) [0|51.1] ""  TEL
 SG_ Mean_Regen_Torque_Rate : 9|9@1+ (1,0) [0|511] ""  TEL
 SG_ Mean_Traction_Torque_Rate : 0|9@1+ (1,0) [0|511] ""  TEL

BO_ 582 Ride_Metric_1: 8 VCU
 SG_ Mean_Regen_Torque : 59|5@1+ (1,0) [0|31] ""  TEL
 SG_ Mean_Traction_Torque : 54|5@1+ (1,0) [0|31] ""  TEL
 SG_ Mean_Rear_BPS : 47|7@1+ (1,0) [0|127] ""  TEL
 SG_ Mean_Front_BPS : 40|7@1+ (1,0) [0|127] ""  TEL
 SG_ Mean_Throttle_Rate : 30|10@1+ (1,0) [0|1023] ""  TEL
 SG_ MeanThrottlePerc : 23|7@1+ (1,0) [0|127] ""  TEL
 SG_ Mean_Speed : 16|7@1+ (1,0) [0|127] ""  TEL
 SG_ Mean_Accel : 9|7@1+ (0.1,0) [0|12.7] ""  TEL
 SG_ Mean_Deccel : 2|7@1+ (0.1,0) [0|12.7] ""  TEL
 SG_ RM_1_Mode : 0|2@1+ (1,0) [0|3] ""  TEL

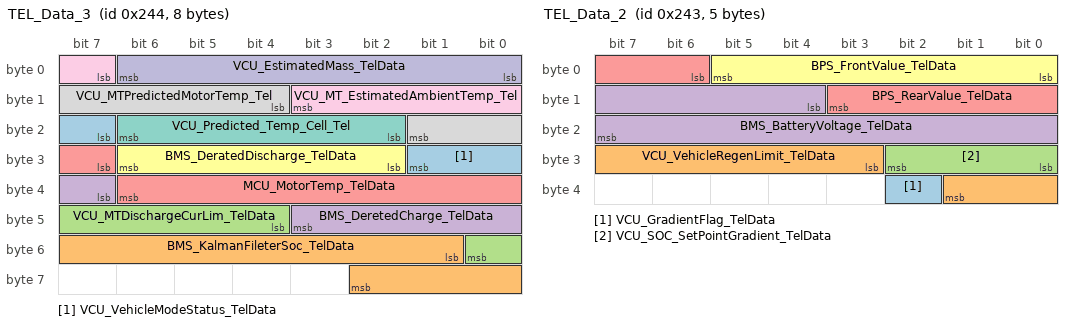
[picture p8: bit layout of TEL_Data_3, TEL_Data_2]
BO_ 580 TEL_Data_3: 8 VCU
 SG_ VCU_VehicleModeStatus_TelData : 23|3@1+ (1,0) [0|7] ""  TEL
 SG_ BMS_KalmanFileterSoc_TelData : 49|10@1+ (0.1,0) [0|102.3] "%"  TEL
 SG_ VCU_MTDischargeCurLim_TelData : 44|5@1+ (5,0) [0|155] "A"  TEL
 SG_ BMS_DeretedCharge_TelData : 39|5@1+ (5,0) [0|155] "A"  TEL
 SG_ MCU_MotorTemp_TelData : 31|8@1+ (1,-40) [-40|215] ""  TEL
 SG_ BMS_DeratedDischarge_TelData : 26|5@1+ (5,0) [0|155] ""  TEL
 SG_ VCU_Predicted_Temp_Cell_Tel : 18|5@1+ (3,0) [0|93] ""  TEL
 SG_ VCU_MTPredictedMotorTemp_Tel : 12|6@1+ (3,0) [0|189] ""  TEL
 SG_ VCU_MT_EstimatedAmbientTemp_Tel : 7|5@1+ (2,0) [0|62] ""  TEL
 SG_ VCU_EstimatedMass_TelData : 0|7@1+ (5,100) [100|735] ""  TEL

BO_ 579 TEL_Data_2: 5 VCU
 SG_ VCU_GradientFlag_TelData : 34|1@1+ (1,0) [0|1] ""  TEL
 SG_ VCU_VehicleRegenLimit_TelData : 27|7@1+ (1,0) [0|127] "A"  TEL
 SG_ VCU_SOC_SetPointGradient_TelData : 24|3@1+ (15,50) [50|155] "A"  TEL
 SG_ BMS_BatteryVoltage_TelData : 12|12@1+ (0.01,20) [20|60.95] "V"  TEL
 SG_ BPS_RearValue_TelData : 6|6@1+ (1,0) [0|63] "Bar"  TEL
 SG_ BPS_FrontValue_TelData : 0|6@1+ (1,0) [0|63] "Bar"  TEL

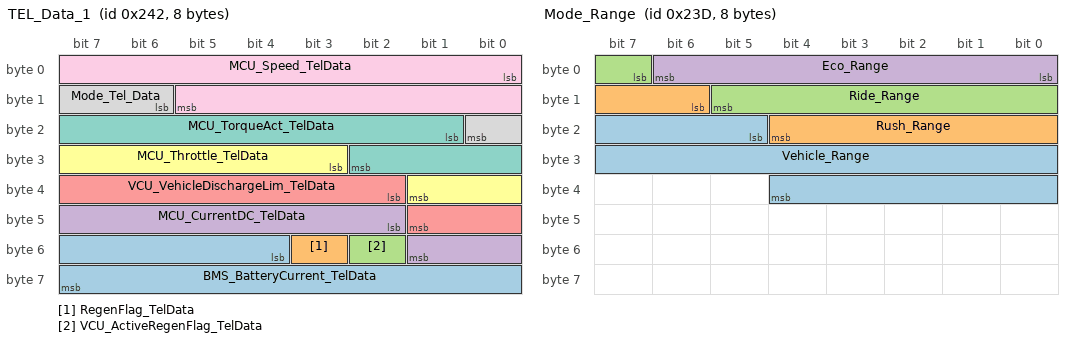
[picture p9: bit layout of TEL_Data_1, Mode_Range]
BO_ 578 TEL_Data_1: 8 VCU
 SG_ BMS_BatteryCurrent_TelData : 52|12@1- (0.1,0) [-204.8|204.7] ""  TEL
 SG_ RegenFlag_TelData : 51|1@1+ (1,0) [0|1] ""  TEL
 SG_ VCU_ActiveRegenFlag_TelData : 50|1@1+ (1,0) [0|1] ""  TEL
 SG_ MCU_CurrentDC_TelData : 42|8@1- (1,40) [-88|167] "A"  TEL
 SG_ VCU_VehicleDischargeLim_TelData : 34|8@1+ (1,0) [0|255] "A"  TEL
 SG_ MCU_Throttle_TelData : 27|7@1+ (1,0) [0|127] "%"  TEL
 SG_ MCU_TorqueAct_TelData : 17|10@1- (0.1,0) [-51.2|51.1] "Nm"  TEL
 SG_ Mode_Tel_Data : 14|3@1+ (1,0) [0|7] ""  TEL
 SG_ MCU_Speed_TelData : 0|14@1- (1,2000) [-6192|10191] ""  TEL

BO_ 573 Mode_Range: 8 VCU
 SG_ Vehicle_Range : 21|16@1+ (0.1,0) [0|6553.5] ""  Tester
 SG_ Rush_Range : 14|7@1+ (1,0) [0|127] ""  Tester
 SG_ Ride_Range : 7|7@1+ (1,0) [0|127] ""  Tester
 SG_ Eco_Range : 0|7@1+ (1,0) [0|127] ""  Tester

BO_ 572 Mode_Odo: 8 VCU
 SG_ Eco_Odo : 42|21@1+ (0.1,0) [0|209715.1] "Km"  TEL
 SG_ Rush_Odo : 21|21@1+ (0.1,0) [0|209715.1] "Km"  TEL
 SG_ Ride_Odo : 0|21@1+ (0.1,0) [0|209715.1] "Km"  TEL

BO_ 571 Battery_Discharge_Capacity_Data: 8 BMS
 SG_ RemainingCapacity_KWh : 56|8@1+ (0.1,0) [0|25.5] "Wh" Vector__XXX
 SG_ RemainingCapacity_Ah : 44|12@1+ (0.1,0) [0|409.5] "" Vector__XXX
 SG_ Discharge_KWh : 24|20@1+ (0.1,0) [0|104857.5] ""  TEL
 SG_ DischargeAh : 0|24@1+ (0.1,0) [0|1677721.5] "Ah"  TEL

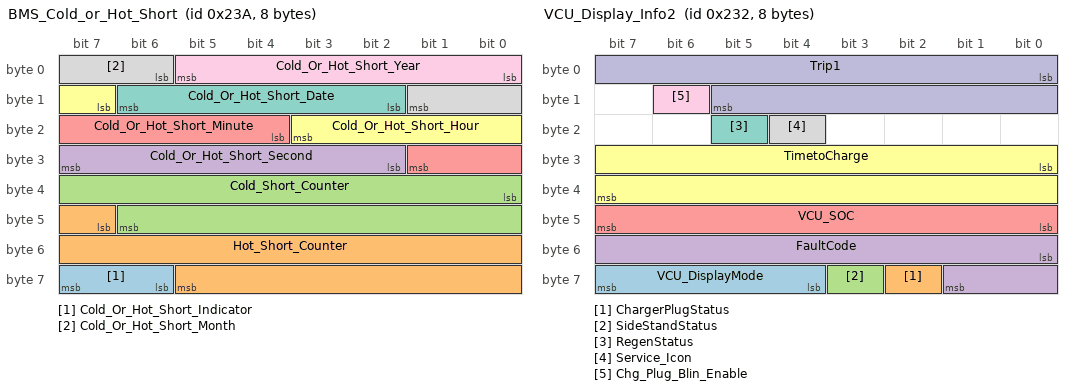
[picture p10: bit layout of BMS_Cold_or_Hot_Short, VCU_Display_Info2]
BO_ 570 BMS_Cold_or_Hot_Short: 8 BMS
 SG_ Cold_Or_Hot_Short_Indicator : 62|2@1+ (1,0) [0|3] "" Vector__XXX
 SG_ Hot_Short_Counter : 47|15@1+ (1,0) [0|32767] ""  VCU
 SG_ Cold_Short_Counter : 32|15@1+ (1,0) [0|32767] ""  VCU
 SG_ Cold_Or_Hot_Short_Second : 26|6@1- (1,0) [0|0] ""  VCU
 SG_ Cold_Or_Hot_Short_Minute : 20|6@1+ (1,0) [0|63] ""  VCU
 SG_ Cold_Or_Hot_Short_Hour : 15|5@1+ (1,0) [0|31] ""  VCU
 SG_ Cold_Or_Hot_Short_Date : 10|5@1+ (1,0) [0|31] ""  VCU
 SG_ Cold_Or_Hot_Short_Month : 6|4@1+ (1,0) [0|15] ""  VCU
 SG_ Cold_Or_Hot_Short_Year : 0|6@1+ (1,0) [0|63] ""  VCU

BO_ 569 Cell_BalancingStatus: 8 BMS
 SG_ vcc_aux_failure_counter : 48|8@1+ (1,0) [0|255] "" Vector__XXX
 SG_ shunt_res_temperature : 32|16@1- (0.01,0) [-327.68|327.67] "" Vector__XXX
 SG_ battery_pack_ambient_temperature : 16|16@1- (0.01,0) [-327.68|327.67] "" Vector__XXX
 SG_ Cell_14_BalancingStatus : 13|1@1+ (1,0) [0|1] ""  TEL
 SG_ Cell_13_BalancingStatus : 12|1@1+ (1,0) [0|1] ""  TEL
 SG_ Cell_12_BalancingStatus : 11|1@1+ (1,0) [0|1] ""  TEL
 SG_ Cell_11_BalancingStatus : 10|1@1+ (1,0) [0|1] ""  TEL
 SG_ Cell_10_BalancingStatus : 9|1@1+ (1,0) [0|1] ""  TEL
 SG_ Cell_9_BalancingStatus : 8|1@1+ (1,0) [0|1] ""  TEL
 SG_ Cell_8_BalancingStatus : 7|1@1+ (1,0) [0|1] ""  TEL
 SG_ Cell_7_BalancingStatus : 6|1@1+ (1,0) [0|1] ""  TEL
 SG_ Cell_6_BalancingStatus : 5|1@1+ (1,0) [0|1] ""  TEL
 SG_ Cell_5_BalancingStatus : 4|1@1+ (1,0) [0|1] ""  TEL
 SG_ Cell_4_BalancingStatus : 3|1@1+ (1,0) [0|1] ""  TEL
 SG_ Cell_3_BalancingStatus : 2|1@1+ (1,0) [0|1] ""  TEL
 SG_ Cell_2_BalancingStatus : 1|1@1+ (1,0) [0|1] ""  TEL
 SG_ Cell_1_BalancingStatus : 0|1@1+ (1,0) [0|0] ""  TEL

BO_ 568 Battery_ChargeData: 8 BMS
 SG_ ChargeAh : 40|24@1+ (0.1,0) [0|6710886.3] "Ah"  TEL,VCU
 SG_ Charge_KWh : 16|24@1+ (0.1,0) [0|1677721.5] "kWh"  TEL,VCU
 SG_ Charge_cycle_Counter : 0|16@1+ (1,0) [0|65535] ""  TEL,VCU

BO_ 567 VCU_MCU_RESET: 6 VCU
 SG_ VCU_MCU_Program_Counter : 16|32@1+ (1,0) [0|4294967295] ""  TEL
 SG_ VCU_MCU_Fault_Type : 8|8@1+ (1,0) [0|255] ""  TEL
 SG_ VCU_MCU_Reset_Type : 0|8@1+ (1,0) [0|255] ""  TEL

BO_ 566 BMS_MCU_RESET: 8 BMS
 SG_ BMS_MCU_Program_Counter : 16|32@1+ (1,0) [0|4294967295] ""  Tester
 SG_ BMS_MCU_Fault_Type : 8|8@1+ (1,0) [0|255] ""  Tester
 SG_ BMS_MCU_Reset_Flag : 0|8@1+ (1,0) [0|255] ""  Tester

BO_ 565 VCU_Avg_Data: 8 VCU
 SG_ AvgThrottle : 48|8@1+ (1,0) [0|255] ""  TEL
 SG_ AvgPower : 32|16@1+ (1,0) [0|65535] "Watt"  TEL
 SG_ AvgCurrent : 16|16@1+ (0.01,0) [0|655.35] "A"  TEL
 SG_ AvgSpeed : 0|16@1+ (0.01,0) [0|655.35] "kmph"  TEL

BO_ 563 VCU_Display_Info3: 8 VCU
 SG_ Brightness_control : 52|4@1+ (1,0) [0|15] "%" Vector__XXX
 SG_ Selected_Trip_Status : 51|1@1+ (1,0) [0|1] ""  Display,TEL
 SG_ ParkArrowBlink : 49|2@1+ (1,0) [0|3] ""  Display,TEL
 SG_ Trip1_Blink : 48|1@1+ (1,0) [0|255] ""  Display,TEL
 SG_ Trip2_Blink : 47|1@1+ (1,0) [0|1] ""  Display,TEL
 SG_ PowerBar : 27|20@1+ (1,0) [0|1048575] ""  Display,TEL
 SG_ Reset : 24|3@1+ (1,0) [0|7] ""  Display,TEL
 SG_ Odo_Reset : 23|1@1+ (1,0) [0|1] ""  Display,TEL
 SG_ Service_Blink : 22|1@1+ (1,0) [0|1] ""  Display,TEL
 SG_ Hibernation : 19|2@1+ (1,0) [0|3] ""  Display,TEL
 SG_ SpeedMode : 17|2@1+ (1,0) [0|0] ""  Display,TEL
 SG_ ParkBlink : 16|1@1+ (1,0) [0|1] ""  Display,TEL
 SG_ Time_Minutes : 8|8@1+ (1,0) [0|255] ""  Display,TEL
 SG_ Am_Pm : 7|1@1+ (1,0) [0|1] ""  Display,TEL
 SG_ Time_Hours : 3|4@1+ (1,0) [0|15] ""  Display,TEL
 SG_ Mode_Blink : 2|1@1+ (1,0) [0|1] ""  Display,TEL
 SG_ SOC_Blink : 1|1@1+ (1,0) [0|1] ""  Display,TEL
 SG_ Speed_Blink : 0|1@1+ (1,0) [0|1] ""  Display,TEL

BO_ 562 VCU_Display_Info2: 8 VCU
 SG_ VCU_DisplayMode : 60|4@1+ (1,0) [0|15] ""  TEL,Display
 SG_ ChargerPlugStatus : 58|1@1+ (1,0) [0|1] ""  TEL,Display
 SG_ SideStandStatus : 59|1@1+ (1,0) [0|1] ""  TEL,Display
 SG_ FaultCode : 48|10@1+ (1,0) [0|1023] ""  TEL,Display
 SG_ VCU_SOC : 40|8@1+ (1,0) [0|255] ""  TEL,Display
 SG_ TimetoCharge : 24|16@1+ (1,0) [0|65535] "min"  TEL,Display
 SG_ RegenStatus : 21|1@1+ (1,0) [0|1] ""  TEL,Display
 SG_ Service_Icon : 20|1@1+ (1,0) [0|1] ""  TEL,Display
 SG_ Chg_Plug_Blin_Enable : 14|1@1+ (1,0) [0|1] ""  TEL,Display
 SG_ Trip1 : 0|14@1+ (0.1,0) [0|1638.3] "Km"  TEL,Display

BO_ 561 VCU_Display_Info1: 8 VCU
 SG_ Display_Range : 56|8@1+ (1,0) [0|255] ""  TEL,Display
 SG_ Total_Odo_VCU : 32|24@1+ (0.1,0) [0|1677721.5] "Km"  TEL,Display
 SG_ Trip2 : 16|14@1+ (0.1,0) [0|1638.3] "Km"  TEL,Display
 SG_ Vehicle_Speed : 0|16@1+ (0.01,0) [0|655.35] "Kph"  TEL,Display

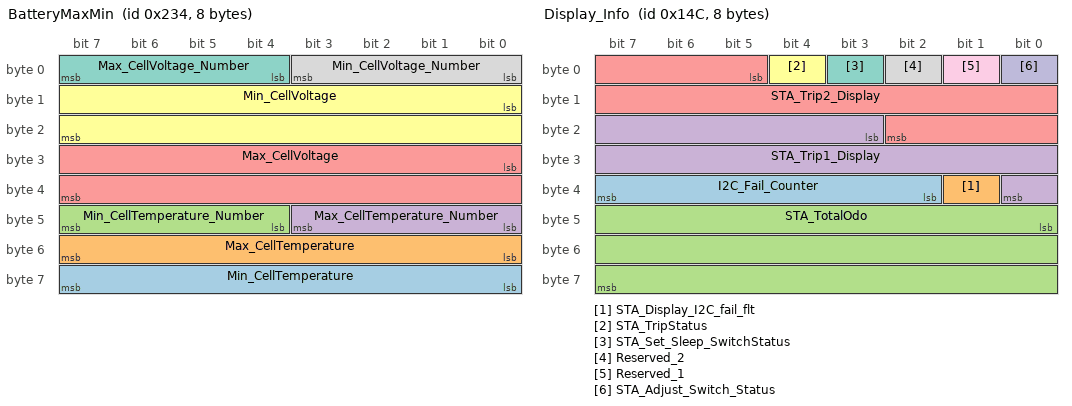
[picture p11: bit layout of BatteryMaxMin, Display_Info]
BO_ 564 BatteryMaxMin: 8 BMS
 SG_ Min_CellTemperature : 56|8@1- (1,0) [-128|127] ""  TEL
 SG_ Max_CellTemperature : 48|8@1- (1,0) [-128|127] ""  TEL
 SG_ Min_CellTemperature_Number : 44|4@1+ (1,0) [0|15] ""  TEL
 SG_ Max_CellTemperature_Number : 40|4@1+ (1,0) [0|15] ""  TEL
 SG_ Max_CellVoltage : 24|16@1+ (0.001,0) [0|65.535] ""  TEL
 SG_ Min_CellVoltage : 8|16@1+ (0.001,0) [0|65.535] ""  TEL
 SG_ Max_CellVoltage_Number : 4|4@1+ (1,0) [0|15] ""  TEL
 SG_ Min_CellVoltage_Number : 0|4@1+ (1,0) [0|15] ""  TEL

BO_ 333 BatteryParameters: 8 BMS
 SG_ SOH : 40|8@1+ (1,0) [0|255] "%"  TEL,VCU
 SG_ Battery_SOCRelative : 32|8@1+ (1,0) [0|255] "%"  TEL,VCU
 SG_ Battery_Voltage : 16|16@1+ (0.001,0) [0|655.35] "V"  TEL,VCU
 SG_ Battery_Current : 0|16@1- (0.01,0) [-327.68|327.67] "A"  TEL,VCU

BO_ 332 Display_Info: 8 Display
 SG_ I2C_Fail_Counter : 34|6@1+ (1,0) [0|63] "" Vector__XXX
 SG_ STA_Display_I2C_fail_flt : 33|1@1+ (1,0) [0|1] "" Vector__XXX
 SG_ STA_TotalOdo : 40|24@1+ (0.1,0) [0|1677721.5] "Km"  TEL,VCU
 SG_ STA_Trip1_Display : 19|14@1+ (0.1,0) [0|1638.3] "Km"  TEL,VCU
 SG_ STA_Trip2_Display : 5|14@1+ (0.1,0) [0|1638.3] "Km"  TEL,VCU
 SG_ STA_TripStatus : 4|1@1+ (1,0) [0|1] ""  TEL,VCU
 SG_ STA_Set_Sleep_SwitchStatus : 3|1@1+ (1,0) [0|1] ""  TEL,VCU
 SG_ Reserved_2 : 2|1@1+ (1,0) [0|1] ""  TEL,VCU
 SG_ Reserved_1 : 1|1@1+ (1,0) [0|1] ""  TEL,VCU
 SG_ STA_Adjust_Switch_Status : 0|1@1+ (1,0) [0|1] ""  TEL,VCU

BO_ 331 BatteryLimits: 8 BMS
 SG_ STA_MaxVoltage : 24|16@1+ (0.001,0) [0|65.535] ""  TEL,VCU
 SG_ STA_ChargingLimit_BMS : 11|7@1+ (1,0) [0|127] ""  TEL,VCU
 SG_ STA_DischargeLimit_BMS : 0|11@1+ (1,0) [0|2047] ""  TEL,VCU

BO_ 329 VCU_Charger_Control: 1 VCU
 SG_ Charger_TX : 6|1@1+ (1,0) [0|1] ""  TEL,Charger
 SG_ Charger_LED_Color : 4|2@1+ (1,0) [0|3] ""  TEL,Charger
 SG_ Charger_LED_Blinks : 0|4@1+ (1,0) [0|15] ""  TEL,Charger

BO_ 327 BMSRequest_CHG_CUR_VOL: 8 BMS
 SG_ TimetoCharge : 32|16@1+ (1,0) [0|65535] "" Vector__XXX
 SG_ Charger_Disable : 48|8@1+ (1,0) [0|255] ""  TEL,Charger
 SG_ BMS_Demand_Voltage : 16|16@1+ (0.01,0) [0|655.35] ""  TEL,Charger
 SG_ BMS_Demand_Current : 0|16@1+ (0.1,0) [0|6553.5] ""  TEL,Charger

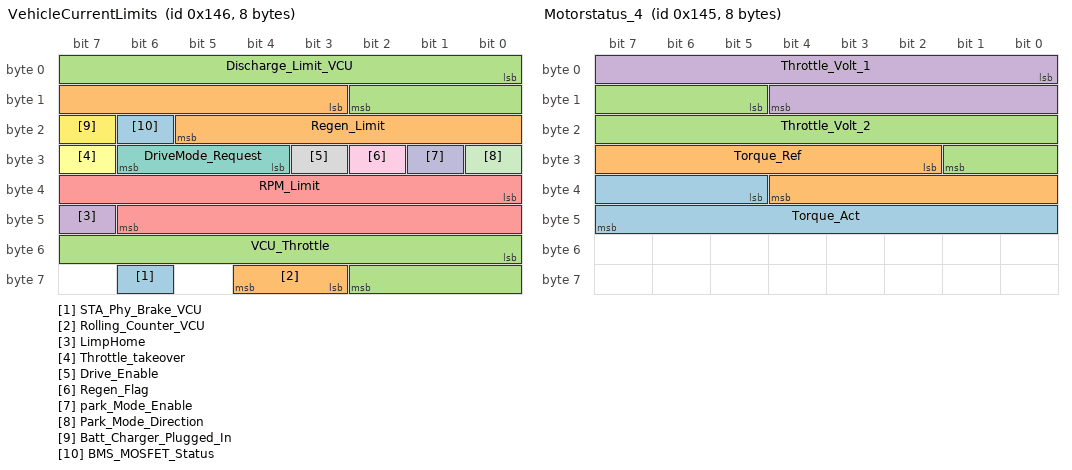
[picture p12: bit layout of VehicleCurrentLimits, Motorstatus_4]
BO_ 326 VehicleCurrentLimits: 8 VCU
 SG_ STA_Phy_Brake_VCU : 62|1@1+ (1,0) [0|1] "" Vector__XXX
 SG_ Rolling_Counter_VCU : 59|2@1+ (1,0) [0|3] "" Vector__XXX
 SG_ VCU_Throttle : 48|11@1- (0.1,0) [-102.4|102.3] ""  TEL,MotorController
 SG_ LimpHome : 47|1@1+ (1,0) [0|1] ""  TEL,MotorController
 SG_ RPM_Limit : 32|15@1- (1,0) [-16384|16383] ""  TEL,MotorController
 SG_ Throttle_takeover : 31|1@1+ (1,0) [0|1] ""  TEL,MotorController
 SG_ DriveMode_Request : 28|3@1+ (1,0) [0|7] ""  TEL,MotorController
 SG_ Drive_Enable : 27|1@1+ (1,0) [0|1] ""  TEL,MotorController
 SG_ Regen_Flag : 26|1@1+ (1,0) [0|0] ""  TEL,MotorController
 SG_ park_Mode_Enable : 25|1@1+ (1,0) [0|1] ""  TEL,MotorController
 SG_ Park_Mode_Direction : 24|1@1+ (1,0) [0|1] ""  TEL,MotorController
 SG_ Batt_Charger_Plugged_In : 23|1@1+ (1,0) [0|1] ""  TEL,MotorController
 SG_ BMS_MOSFET_Status : 22|1@1+ (1,0) [0|1] ""  TEL,MotorController
 SG_ Regen_Limit : 11|11@1+ (1,0) [0|2047] "A"  TEL,MotorController
 SG_ Discharge_Limit_VCU : 0|11@1+ (1,0) [0|2047] ""  TEL,MotorController

BO_ 325 Motorstatus_4: 8 MotorController
 SG_ Torque_Act : 37|11@1- (0.1,0) [-102.4|102.3] ""  Tester,TEL
 SG_ Torque_Ref : 26|11@1- (0.1,0) [-102.4|102.3] "Nm"  Tester,TEL
 SG_ Throttle_Volt_2 : 13|13@1+ (1,0) [0|8191] ""  Tester,TEL
 SG_ Throttle_Volt_1 : 0|13@1+ (1,0) [0|8191] "mV"  Tester,TEL

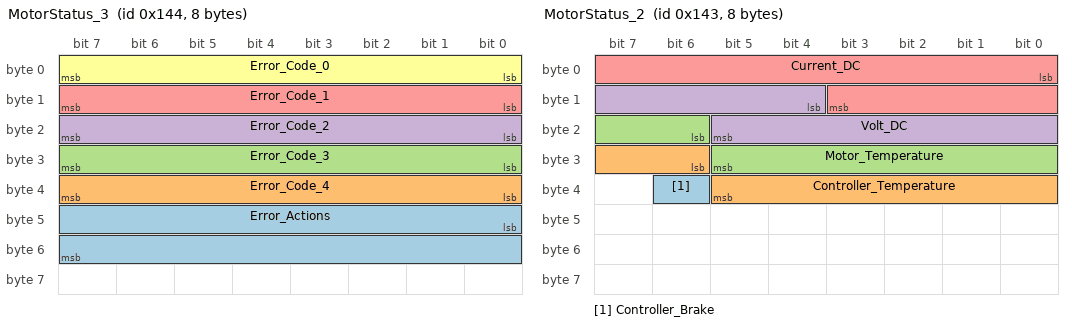
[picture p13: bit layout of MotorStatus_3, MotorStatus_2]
BO_ 324 MotorStatus_3: 8 MotorController
 SG_ Error_Actions : 40|16@1+ (1,0) [0|65535] ""  VCU,TEL
 SG_ Error_Code_4 : 32|8@1+ (1,0) [0|255] ""  VCU,TEL
 SG_ Error_Code_3 : 24|8@1+ (1,0) [0|255] ""  VCU,TEL
 SG_ Error_Code_2 : 16|8@1+ (1,0) [0|255] ""  VCU,TEL
 SG_ Error_Code_1 : 8|8@1+ (1,0) [0|255] ""  VCU,TEL
 SG_ Error_Code_0 : 0|8@1+ (1,0) [0|255] ""  VCU,TEL

BO_ 323 MotorStatus_2: 8 MotorController
 SG_ Controller_Brake : 38|1@1+ (1,0) [0|1] ""  TEL,VCU
 SG_ Controller_Temperature : 30|8@1+ (1,-40) [-40|215] "degC"  TEL,VCU
 SG_ Motor_Temperature : 22|8@1+ (1,-40) [-40|215] "degC"  TEL,VCU
 SG_ Volt_DC : 12|10@1+ (0.1,0) [0|102.3] ""  TEL,VCU
 SG_ Current_DC : 0|12@1- (1,0) [-2048|2047] "A"  TEL,VCU

BO_ 321 BatteryStatus: 8 BMS
 SG_ STA_DC_DC_Enable_G4 : 23|1@1+ (1,0) [0|1] "" Vector__XXX
 SG_ STA_PFET_STS : 22|1@1+ (1,0) [0|1] "" Vector__XXX
 SG_ STA_MCU_14V_PG : 21|1@1+ (1,0) [0|1] "" Vector__XXX
 SG_ STA_BMS_MCU_5V_PG : 20|1@1+ (1,0) [0|1] "" Vector__XXX
 SG_ STA_BMS_SCD : 19|1@1+ (1,0) [0|1] "" Vector__XXX
 SG_ STA_BMS_VCU_AuthStatus : 5|2@1+ (1,0) [0|3] ""  Tester,VCU,TEL
 SG_ STA_AutoHyber_Timeout_status : 18|1@1+ (1,0) [0|1] ""  Tester,VCU,TEL
 SG_ STA_CAN_BusOFF_Status : 17|1@1+ (1,0) [0|1] ""  Tester,VCU,TEL
 SG_ STA_OCC_Latch : 16|1@1+ (1,0) [0|1] ""  Tester,VCU,TEL
 SG_ STA_OCD_Latch : 15|1@1+ (1,0) [0|1] ""  Tester,VCU,TEL
 SG_ STA_BatteryFull : 14|1@1+ (1,0) [0|1] ""  Tester,VCU,TEL
 SG_ STA_Load_V_Present : 13|1@1+ (1,0) [0|1] ""  Tester,VCU,TEL
 SG_ STA_CFET_Status : 12|1@1+ (1,0) [0|1] ""  Tester,VCU,TEL
 SG_ STA_PPINStatus_BMS : 11|1@1+ (1,0) [0|1] ""  Tester,VCU,TEL
 SG_ STA_KeyStatus_BMS : 10|1@1+ (1,0) [0|1] ""  Tester,VCU,TEL
 SG_ STA_Precharging_Status : 8|2@1+ (1,0) [0|3] ""  Tester,VCU,TEL
 SG_ STA_DFET_Status : 7|1@1+ (1,0) [0|1] ""  Tester,VCU,TEL
 SG_ STA_BMS_FaultStatus : 4|1@1+ (1,0) [0|1] ""  Tester,VCU,TEL
 SG_ STA_BMS_Status : 0|4@1+ (1,0) [0|15] ""  Tester,VCU,TEL

BO_ 70 BMS_SYSTEM_FAILURE: 8 BMS
 SG_ FLT_System_Dig_init_FaultCode : 0|32@1+ (1,0) [0|4294967295] ""  VCU

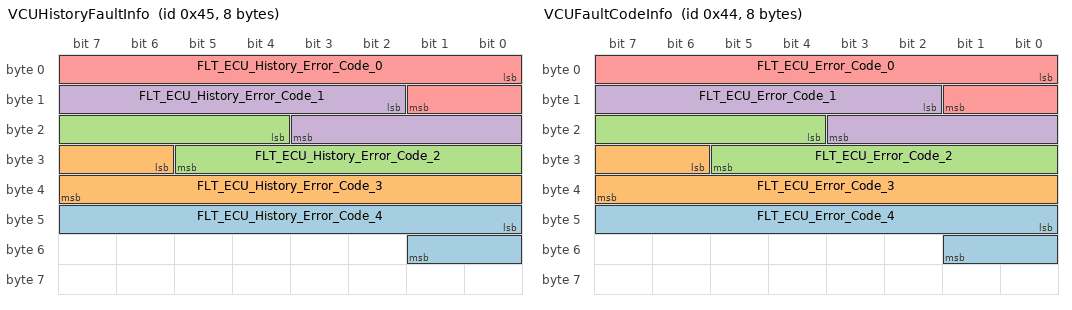
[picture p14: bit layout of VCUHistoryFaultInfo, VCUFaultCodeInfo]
BO_ 69 VCUHistoryFaultInfo: 8 VCU
 SG_ FLT_ECU_History_Error_Code_4 : 40|10@1+ (1,0) [0|1023] ""  Tester
 SG_ FLT_ECU_History_Error_Code_3 : 30|10@1+ (1,0) [0|1023] ""  Tester
 SG_ FLT_ECU_History_Error_Code_2 : 20|10@1+ (1,0) [0|1023] ""  Tester
 SG_ FLT_ECU_History_Error_Code_1 : 10|10@1+ (1,0) [0|1023] ""  Tester
 SG_ FLT_ECU_History_Error_Code_0 : 0|10@1+ (1,0) [0|1023] ""  Tester

BO_ 68 VCUFaultCodeInfo: 8 VCU
 SG_ FLT_ECU_Error_Code_4 : 40|10@1+ (1,0) [0|1023] ""  Tester
 SG_ FLT_ECU_Error_Code_3 : 30|10@1+ (1,0) [0|1023] ""  Tester
 SG_ FLT_ECU_Error_Code_2 : 20|10@1+ (1,0) [0|1023] ""  Tester
 SG_ FLT_ECU_Error_Code_1 : 10|10@1+ (1,0) [0|1023] ""  Tester
 SG_ FLT_ECU_Error_Code_0 : 0|10@1+ (1,0) [0|1023] ""  Tester

BO_ 67 VcuFaultTimeoutInfo: 8 VCU
 SG_ FLT_CAN_H_G_or_L_VCC : 16|1@1+ (1,0) [0|1] "" Vector__XXX
 SG_ FLT_LowSoc_RTD_Cutoff : 11|1@1+ (1,0) [0|1] ""  Tester,TEL
 SG_ FLT_Supply3v3_Fault : 10|1@1+ (1,0) [0|1] ""  Tester,TEL
 SG_ FLT_Indicator_One_FaultFlag : 9|1@1+ (1,0) [0|1] ""  Tester,TEL
 SG_ FLT_Indicator_Two_FaultFlag : 15|1@1+ (1,0) [0|1] ""  Tester,TEL
 SG_ FLT_DRL_FaultFlag : 14|1@1+ (1,0) [0|1] ""  Tester,TEL
 SG_ FLT_HighBeam_FaultFlag : 13|1@1+ (1,0) [0|1] ""  Tester,TEL
 SG_ FLT_BrakeLamp_Fault : 12|1@1+ (1,0) [0|1] ""  Tester,TEL
 SG_ FLT_CAN_H_L_Short : 8|1@1+ (1,0) [0|1] ""  Tester,TEL
 SG_ FLT_VCU_BMS_AuthFault : 7|1@1+ (1,0) [0|1] ""  Tester,TEL
 SG_ FLT_BMS_PPin_Error : 6|1@1+ (1,0) [0|1] ""  Tester,TEL
 SG_ FLT_BMS_CANMsg_Timeout : 5|1@1+ (1,0) [0|1] ""  Tester,TEL
 SG_ FLT_Charger_CANMsg_Timeout : 4|1@1+ (1,0) [0|1] ""  Tester,TEL
 SG_ FLT_TEL_CANMsg_Timeout : 3|1@1+ (1,0) [0|1] ""  Tester,TEL
 SG_ FLT_Display_CANMsg_Timeout : 2|1@1+ (1,0) [0|1] ""  Tester,TEL
 SG_ FLT_MCU_CANMsg_Timeout : 1|1@1+ (1,0) [0|1] ""  Tester,TEL
 SG_ FLT_BMS_KeyError : 0|1@1+ (1,0) [0|1] ""  Tester,TEL

BO_ 65 BatteryFaultInfo: 8 BMS
 SG_ Precharge_stage_check_fail : 40|3@1+ (1,0) [0|7] "" Vector__XXX
 SG_ FLT_Fuse_Error_Flag_G4 : 39|1@1+ (1,0) [0|1] "" Vector__XXX
 SG_ FLT_Prchg_Permanent_Fail_Status : 35|1@1+ (1,0) [0|1] "" Vector__XXX
 SG_ FLT_MOSFET_Failure : 36|1@1+ (1,0) [0|1] "" Vector__XXX
 SG_ FLT_Uvlo : 34|1@1+ (1,0) [0|1] ""  TEL,VCU
 SG_ FLT_vcc_aux_fail : 33|1@1+ (1,0) [0|1] ""  TEL,VCU
 SG_ FLT_CellTemp_Imbalance : 32|1@1+ (1,0) [0|1] ""  TEL,VCU
 SG_ FLT_Motor_CANTimeout_BMS : 31|1@1+ (1,0) [0|1] ""  TEL,VCU
 SG_ FLT_Charger_CANTimeout_BMS : 30|1@1+ (1,0) [0|1] ""  TEL,VCU
 SG_ FLT_CellVolt_DeepDischarge : 29|1@1+ (1,0) [0|1] ""  TEL,VCU
 SG_ FLT_Cell_upnormalVoltage : 27|2@1+ (1,0) [0|3] ""  TEL,VCU
 SG_ FLT_BattChargingTempFault : 24|3@1+ (1,0) [0|7] ""  TEL,VCU
 SG_ FLT_VCU_PPIn_Error : 23|1@1+ (1,0) [0|1] ""  TEL,VCU
 SG_ FLT_BMS_ChargerVoltSenseFault : 22|1@1+ (1,0) [0|1] ""  TEL,VCU
 SG_ FLT_BattDFET_TempFault : 20|2@1+ (1,0) [0|3] ""  TEL,VCU
 SG_ FLT_VCU_KeyError : 19|1@1+ (1,0) [0|1] ""  TEL,VCU
 SG_ FLT_BattCFET_TempFault : 17|2@1+ (1,0) [0|3] ""  TEL,VCU
 SG_ FLT_VCU_CANMsgTimeout : 16|1@1+ (1,0) [0|1] ""  TEL,VCU
 SG_ FLT_AFE_CommFault : 15|1@1+ (1,0) [0|1] ""  TEL,VCU
 SG_ FLT_CellVoltageFault : 12|3@1+ (1,0) [0|7] ""  TEL,VCU
 SG_ FLT_BattVoltageFault : 9|3@1+ (1,0) [0|7] ""  TEL,VCU
 SG_ FLT_CellVoltageMissmatch : 8|1@1+ (1,0) [0|1] ""  TEL,VCU
 SG_ FLT_BattThermalRunawayFlt : 7|1@1+ (1,0) [0|1] ""  TEL,VCU
 SG_ FLT_BattDischTempFault : 4|3@1+ (1,0) [0|7] ""  TEL,VCU
 SG_ FLT_BatteryCurrentFault : 1|3@1+ (1,0) [0|7] ""  TEL,VCU
 SG_ FLT_BattDisch_ShortCircuit : 0|1@1+ (1,0) [0|1] ""  TEL,VCU

BO_ 54 ChargerAck: 6 Charger
 SG_ charger_temp : 32|8@1+ (1,-40) [-40|215] ""  TEL,VCU,BMS
 SG_ settle_voltage : 16|16@1+ (0.01,0) [-327.68|327.67] ""  TEL,VCU,BMS
 SG_ settle_current : 0|16@1+ (0.1,0) [0|6553.5] ""  TEL,VCU,BMS

BO_ 53 BMSChargerAckmsg: 1 Charger
 SG_ bms_send_char_ack_msg : 0|8@1+ (1,0) [0|255] ""  BMS

BO_ 52 BMSCANCommandAckMsg: 8 BMS
 SG_ PrechargePermanent_Fail_Recovery : 16|8@1+ (1,0) [0|255] ""  VCU
 SG_ Calibration_Ack_Status : 8|8@1+ (1,0) [0|255] ""  VCU
 SG_ bms_turn_off_ack : 0|1@1+ (1,0) [0|1] ""  VCU

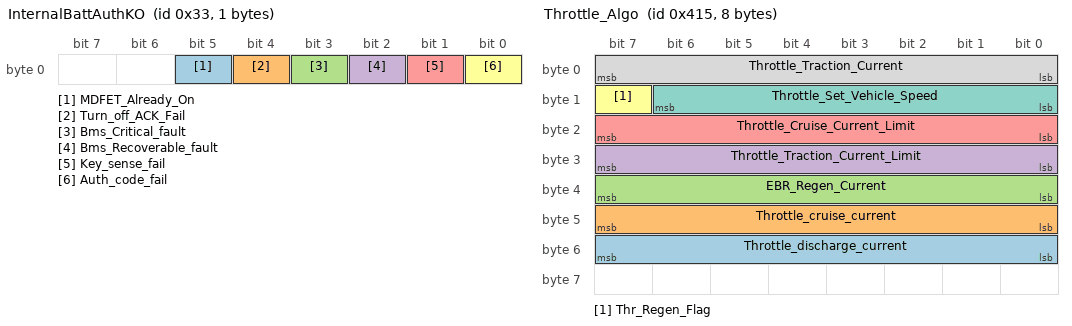
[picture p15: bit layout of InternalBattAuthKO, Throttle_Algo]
BO_ 51 InternalBattAuthKO: 1 BMS
 SG_ MDFET_Already_On : 5|1@1+ (1,0) [0|1] ""  VCU
 SG_ Turn_off_ACK_Fail : 4|1@1- (1,0) [-1|0] ""  VCU
 SG_ Bms_Critical_fault : 3|1@1+ (1,0) [0|1] ""  VCU
 SG_ Bms_Recoverable_fault : 2|1@1+ (1,0) [0|1] ""  VCU
 SG_ Key_sense_fail : 1|1@1+ (1,0) [0|1] ""  VCU
 SG_ Auth_code_fail : 0|1@1+ (1,0) [0|1] ""  VCU

BO_ 50 VcuAuth: 5 VCU
 SG_ vcu_public_key : 32|8@1+ (1,0) [0|255] ""  BMS
 SG_ auth_code : 0|32@1+ (1,0) [0|4294967295] ""  BMS

BO_ 49 InternalBattAuthOK: 4 BMS
 SG_ bms_software_version_no : 8|16@1+ (0.01,0) [0|655.35] ""  VCU
 SG_ mcu1_public_key : 0|8@1+ (1,0) [0|255] ""  VCU

BO_ 32 VCUTurnOFF: 1 VCU
 SG_ Dummy_byte : 0|8@1+ (1,0) [0|255] ""  BMS

BO_ 629 Battery_Deration_Model_Output4: 8 BMS
 SG_ RMS_Cell_Heat_Gen_j : 32|16@1+ (1,0) [0|65535] ""  Tester
 SG_ Htc_casing_ambient : 16|16@1+ (1,0) [0|65535] ""  Tester
 SG_ Heat_Stored_pcm : 0|16@1- (1,0) [-32768|32767] ""  Tester

BO_ 1047 Mass_Estimation_Algo: 8 VCU
 SG_ Estimated_mass : 48|16@1+ (0.01,0) [0|655.35] ""  Tester
 SG_ Mass_Obs : 32|16@1+ (0.01,0) [0|655.35] "ms^2"  Tester
 SG_ Resultant_force : 24|8@1+ (8,-1000) [-1000|1040] ""  Tester
 SG_ Mass_Calc : 8|16@1+ (1,0) [0|65535] "Kg"  Tester
 SG_ Observed_Acceleration : 0|8@1+ (0.16,-20) [-20|20.8] "ms^2"  Tester

BO_ 1045 Throttle_Algo: 8 VCU
 SG_ Throttle_discharge_current : 48|8@1+ (1,0) [0|255] "A"  Tester
 SG_ Throttle_cruise_current : 40|8@1+ (1,0) [0|255] "A"  Tester
 SG_ EBR_Regen_Current : 32|8@1- (1,0) [-128|127] ""  Tester
 SG_ Throttle_Traction_Current_Limit : 24|8@1+ (1,0) [0|255] ""  Tester
 SG_ Throttle_Cruise_Current_Limit : 16|8@1+ (1,0) [0|255] "A"  Tester
 SG_ Thr_Regen_Flag : 15|1@1+ (1,0) [0|1] ""  Tester
 SG_ Throttle_Set_Vehicle_Speed : 8|7@1- (1,0) [-64|63] "Kph"  Tester
 SG_ Throttle_Traction_Current : 0|8@1+ (1,0) [0|255] ""  Tester

BO_ 1043 Range_Estimation: 8 VCU
 SG_ Range_Init : 48|16@1+ (0.01,0) [0|655.35] ""  Tester
 SG_ Add_Model_Range : 32|16@1+ (0.01,0) [0|655.35] ""  Tester
 SG_ Clipped_Range : 16|16@1+ (1,0) [0|65535] ""  Tester
 SG_ Range : 0|16@1+ (0.01,0) [0|655.35] ""  Tester

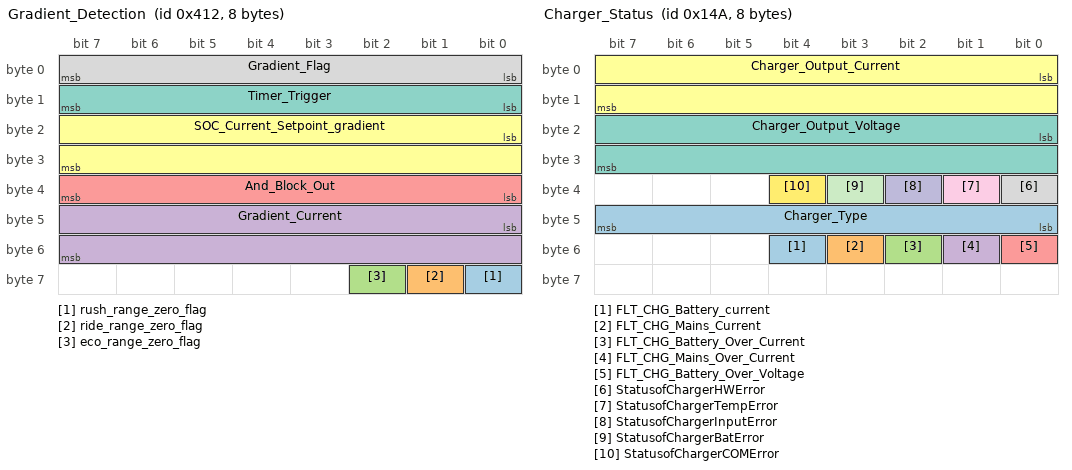
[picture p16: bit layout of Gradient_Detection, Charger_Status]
BO_ 1042 Gradient_Detection: 8 VCU
 SG_ rush_range_zero_flag : 56|1@1+ (1,0) [0|1] "" Vector__XXX
 SG_ ride_range_zero_flag : 57|1@1+ (1,0) [0|1] "" Vector__XXX
 SG_ eco_range_zero_flag : 58|1@1+ (1,0) [0|1] "" Vector__XXX
 SG_ Gradient_Current : 40|16@1+ (0.01,0) [0|655.35] ""  Tester
 SG_ And_Block_Out : 32|8@1+ (1,0) [0|255] ""  Tester
 SG_ SOC_Current_Setpoint_gradient : 16|16@1+ (0.01,0) [0|655.35] ""  Tester
 SG_ Timer_Trigger : 8|8@1+ (1,0) [0|255] ""  Tester
 SG_ Gradient_Flag : 0|8@1+ (1,0) [0|255] ""  Tester

BO_ 1048 Active_Regen_Algo: 8 VCU
 SG_ Regen_Torque_Slip_Lim : 24|8@1- (1,0) [-128|127] "Nm"  Tester
 SG_ Regen_Torque_Rpm_Lim : 16|8@1- (1,0) [-128|127] "Nm"  Tester
 SG_ Regen_Force_Mass_Lim : 8|8@1- (8,0) [-1024|1016] "N"  Tester
 SG_ Active_Regen_Flag : 0|1@1+ (1,0) [0|1] ""  Tester

BO_ 1050 ais_2_msg: 8 VCU
 SG_ ais_regen_current : 56|8@1+ (1,0) [0|255] "" Vector__XXX
 SG_ ais_regen_flag : 7|1@1+ (1,0) [0|1] "" Vector__XXX
 SG_ ais_motor_torque : 8|16@1+ (0.1,0) [0|6553.5] "" Vector__XXX
 SG_ ais_thr_perc : 24|16@1+ (0.1,0) [0|6553.5] "" Vector__XXX

BO_ 1049 ais_1_msg: 8 VCU
 SG_ speed_max_kph : 40|8@1+ (1,0) [0|255] "" Vector__XXX
 SG_ max_torque_nm : 32|8@1+ (1,0) [0|255] "" Vector__XXX
 SG_ whpkm_avg : 0|16@1+ (0.1,0) [0|6553.5] "" Vector__XXX

BO_ 1055 VCU_DTC_Algo_2: 8 VCU
 SG_ dtc_final_throttle : 32|16@1+ (0.1,0) [0|6553.5] "" Vector__XXX
 SG_ dtc_slip_detect : 24|8@1+ (1,0) [0|255] "" Vector__XXX
 SG_ dtc_motor_decel_g : 16|8@1- (0.1,0) [-12.8|12.7] "" Vector__XXX
 SG_ bandpass_out : 48|16@1+ (0.1,0) [0|6553.5] "" Vector__XXX
 SG_ bandpass_mavg : 0|16@1+ (0.1,0) [0|6553.5] "" Vector__XXX

BO_ 1054 VCU_DTC_Algo_1: 8 VCU
 SG_ dtc_hit_mitigation_throttle : 48|16@1+ (0.1,0) [0|6553.5] "" Vector__XXX
 SG_ dtc_on_flag : 32|8@1+ (1,0) [0|255] "" Vector__XXX
 SG_ dtc_slip_ratio : 40|8@1- (0.01,0) [-1.28|1.27] "" Vector__XXX
 SG_ dtc_ideal_line_kph : 16|16@1- (0.1,0) [-3276.8|3276.7] "" Vector__XXX
 SG_ dtc_throttle : 0|16@1+ (0.1,0) [0|6553.5] "" Vector__XXX

BO_ 336 VCU_DTU_Status: 8 VCU
 SG_ Batt_High_Temp_FLT : 14|1@1+ (1,0) [0|1] "" Vector__XXX
 SG_ Hill_Hold_Status_VCU : 17|3@1+ (1,0) [0|7] "" Vector__XXX
 SG_ Warning_Error_code_new : 16|1@1+ (1,0) [0|0] "" Vector__XXX
 SG_ Batt_Thermal_Runaway_new : 15|1@1+ (1,0) [0|0] "" Vector__XXX
 SG_ Batt_full_charge_new : 13|1@1+ (1,0) [0|0] "" Vector__XXX
 SG_ chg_ppin_fault_new : 12|1@1+ (1,0) [0|0] "" Vector__XXX
 SG_ chg_solenoid_feedback_new : 11|1@1+ (1,0) [0|0] "" Vector__XXX
 SG_ Chg_PPin_fault_new : 10|1@1+ (1,0) [0|0] "" Vector__XXX
 SG_ Odo_Reset_new : 9|1@1+ (1,0) [0|0] "" Vector__XXX
 SG_ Limp_Mode_new : 8|1@1+ (1,0) [0|0] "" Vector__XXX
 SG_ Hill_Hold_new : 7|1@1+ (1,0) [0|0] "" Vector__XXX
 SG_ speed_blink_new : 6|1@1+ (1,0) [0|0] "" Vector__XXX
 SG_ side_stand_Blink_new : 5|1@1+ (1,0) [0|0] "" Vector__XXX
 SG_ Side_Stand_status_new : 4|1@1+ (1,0) [0|0] "" Vector__XXX
 SG_ Regen_status_new : 3|1@1+ (1,0) [0|0] "" Vector__XXX
 SG_ Service_Blink_new : 2|1@1+ (1,0) [0|0] "" Vector__XXX
 SG_ service_Icon_new : 1|1@1+ (1,0) [0|0] "" Vector__XXX
 SG_ Key_connect_state_new : 0|1@1+ (1,0) [0|0] "" Vector__XXX

BO_ 591 VCU_DTU_Data: 8 VCU
 SG_ VCU_displayMode_new : 42|4@1+ (1,0) [0|15] "" Vector__XXX
 SG_ speed_mode_new : 40|2@1+ (1,0) [0|0] "" Vector__XXX
 SG_ VCU_SOC_new : 32|8@1+ (1,0) [0|255] "" Vector__XXX
 SG_ timetocharge_new : 16|16@1+ (1,0) [0|65535] "Min" Vector__XXX
 SG_ Vehicle_speed_new : 0|16@1+ (0.01,0) [0|655.35] "kmp" Vector__XXX

BO_ 590 VCU_DTU_Params: 8 VCU
 SG_ Display_range_new : 56|8@1+ (1,0) [0|255] "" Vector__XXX
 SG_ Total_Odo_VCU_new : 32|24@1+ (0.1,0) [0|1677721.5] "km" Vector__XXX
 SG_ Trip2_new : 16|14@1+ (0.1,0) [0|1638.3] "km" Vector__XXX
 SG_ Trip1_new : 0|14@1+ (0.1,0) [0|1638.3] "km" Vector__XXX

BO_ 330 Charger_Status: 8 Charger
 SG_ FLT_CHG_Battery_current : 52|1@1+ (1,0) [0|1] "" Vector__XXX
 SG_ FLT_CHG_Mains_Current : 51|1@1+ (1,0) [0|1] "" Vector__XXX
 SG_ FLT_CHG_Battery_Over_Current : 50|1@1+ (1,0) [0|1] "" Vector__XXX
 SG_ FLT_CHG_Mains_Over_Current : 49|1@1+ (1,0) [0|1] "" Vector__XXX
 SG_ FLT_CHG_Battery_Over_Voltage : 48|1@1+ (1,0) [0|1] "" Vector__XXX
 SG_ Charger_Output_Current : 0|16@1+ (0.1,0) [0|6553.5] ""  Vehicle
 SG_ Charger_Output_Voltage : 16|16@1+ (0.01,0) [0|655.35] ""  Vehicle
 SG_ StatusofChargerHWError : 32|1@1+ (1,0) [0|1] ""  Vehicle
 SG_ StatusofChargerTempError : 33|1@1+ (1,0) [0|1] ""  Vehicle
 SG_ StatusofChargerInputError : 34|1@1+ (1,0) [0|1] ""  Vehicle
 SG_ StatusofChargerBatError : 35|1@1+ (1,0) [0|1] ""  Vehicle
 SG_ StatusofChargerCOMError : 36|1@1+ (1,0) [0|1] ""  Vehicle
 SG_ Charger_Type : 40|8@1+ (1,0) [0|255] ""  Vehicle

BO_ 328 VCU_Status: 8 VCU
 SG_ STA_Right_Ind_switch_Status : 35|1@1+ (1,0) [0|1] "" Vector__XXX
 SG_ STA_Left_Indicator_switch_Status : 34|1@1+ (1,0) [0|1] "" Vector__XXX
 SG_ STA_Right_Brake_Switch_Status : 33|1@1+ (1,0) [0|1] "" Vector__XXX
 SG_ STA_Left_Brake_Switch_Status : 32|1@1+ (1,0) [0|1] "" Vector__XXX
 SG_ STA_Open_Key_Status_RY : 36|1@1+ (1,0) [0|1] "" Vector__XXX
 SG_ STA_DCDC_Enable_Status : 31|1@1+ (1,0) [0|1] "" Vector__XXX
 SG_ STA_Authentication_Status : 30|1@1+ (1,0) [-1|0] "" Vector__XXX
 SG_ STA_Solenoid_attempt_status : 28|2@1+ (1,0) [0|3] "" Vector__XXX
 SG_ STA_Right_Mode_Switch_status : 27|1@1+ (1,0) [0|1] "" Vector__XXX
 SG_ STA_Left_Mode_Switch_status : 26|1@1+ (1,0) [0|1] "" Vector__XXX
 SG_ STA_Charging_Enable : 25|1@1+ (1,0) [0|1] "" Vector__XXX
 SG_ STA_Service_Mode_Active : 24|1@1+ (1,0) [0|1] "" Vector__XXX
 SG_ STA_Error_State : 22|2@1+ (1,0) [0|3] ""  BMS,TEL
 SG_ STA_Hybernation_Seq_Enable : 21|1@1+ (1,0) [0|1] ""  BMS,TEL
 SG_ STA_Boot_Status : 20|1@1+ (1,0) [0|1] ""  BMS,TEL
 SG_ STA_Solenoid_FeedbackStatus : 19|1@1+ (1,0) [0|1] ""  BMS,TEL
 SG_ STA_Buzzer_Status : 18|1@1+ (1,0) [0|1] ""  BMS,TEL
 SG_ STA_Traction_Mode_Status : 15|3@1+ (1,0) [0|7] ""  BMS,TEL
 SG_ STA_VCU_LED_BlinkStatus : 14|1@1+ (1,0) [0|1] ""  BMS,TEL
 SG_ STA_KeyConnectionStatus_VCU : 13|1@1+ (1,0) [0|1] ""  BMS,TEL
 SG_ STA_VehicleModeStatus : 9|4@1+ (1,0) [0|15] ""  BMS,TEL
 SG_ STA_PPINStatus_VCU : 8|1@1+ (1,0) [0|1] ""  BMS,TEL
 SG_ STA_RTD_Flag : 7|1@1+ (1,0) [0|1] ""  BMS,TEL
 SG_ STA_DisplaySupplyStatus : 6|1@1+ (1,0) [0|1] ""  BMS,TEL
 SG_ STA_KillSwitchStatus : 5|1@1+ (1,0) [0|1] ""  BMS,TEL
 SG_ STA_SideStandStatus : 4|1@1+ (1,0) [0|1] ""  BMS,TEL
 SG_ STA_BrakeStatus : 3|1@1+ (1,0) [0|1] ""  BMS,TEL
 SG_ STA_IndicatorSwitchStatus : 2|1@1+ (1,0) [0|1] ""  BMS,TEL
 SG_ STA_Park_Switch : 1|1@1+ (1,0) [0|1] ""  BMS,TEL
 SG_ STA_IgnitionSwitchStatus : 0|1@1+ (1,0) [0|1] ""  BMS,TEL

BO_ 337 Display_Info_2: 8 Display
 SG_ Headlamp_Icon_DIS_Status : 2|1@1+ (1,0) [0|1] ""  VCU
 SG_ Indicator_Right_DIS_status : 1|1@1+ (1,0) [0|1] ""  VCU
 SG_ Indicator_Left_DIS_Status : 0|1@1+ (1,0) [0|1] ""  VCU

BO_ 617 Tel_Data_Enable: 5 VCU
 SG_ Vcu_Tel_Data_enable : 0|1@1+ (1,0) [0|1] ""  TEL

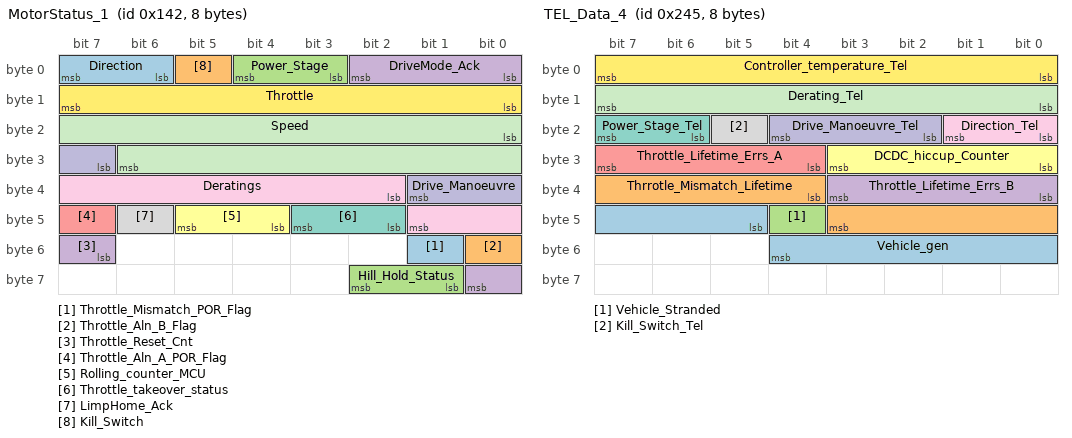
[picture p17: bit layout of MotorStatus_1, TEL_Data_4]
BO_ 322 MotorStatus_1: 8 MotorController
 SG_ Throttle_Mismatch_POR_Flag : 49|1@1+ (1,0) [0|1] "" Vector__XXX
 SG_ Throttle_Aln_B_Flag : 48|1@1+ (1,0) [0|1] "" Vector__XXX
 SG_ Hill_Hold_Status : 57|2@1+ (1,0) [0|3] "" Vector__XXX
 SG_ Throttle_Reset_Cnt : 55|2@1+ (1,0) [0|3] "" Vector__XXX
 SG_ Throttle_Aln_A_POR_Flag : 47|1@1+ (1,0) [0|1] "" Vector__XXX
 SG_ Rolling_counter_MCU : 44|2@1+ (1,0) [0|3] "" Vector__XXX
 SG_ Throttle_takeover_status : 42|2@1+ (1,0) [0|1] "" Vector__XXX
 SG_ LimpHome_Ack : 46|1@1+ (1,0) [0|1] ""  TEL,VCU
 SG_ Deratings : 34|8@1+ (1,0) [0|1] ""  TEL,VCU
 SG_ Drive_Manoeuvre : 31|3@1+ (1,0) [0|0] ""  TEL,VCU
 SG_ Speed : 16|15@1- (1,0) [-16384|16383] "rpm"  TEL,VCU
 SG_ Throttle : 8|8@1- (1,0) [-128|127] "%"  TEL,VCU
 SG_ Direction : 6|2@1+ (1,0) [0|3] ""  TEL,VCU
 SG_ Kill_Switch : 5|1@1+ (1,0) [0|1] ""  TEL,VCU
 SG_ Power_Stage : 3|2@1+ (1,0) [0|3] ""  TEL,VCU
 SG_ DriveMode_Ack : 0|3@1+ (1,0) [0|7] ""  TEL,VCU

BO_ 581 TEL_Data_4: 8 VCU
 SG_ Vehicle_gen : 45|8@1+ (0.1,0) [0|25.5] "" Vector__XXX
 SG_ Thrrotle_Mismatch_Lifetime : 36|8@1+ (1,0) [0|255] "" Vector__XXX
 SG_ Vehicle_Stranded : 44|1@1+ (1,0) [0|1] "" Vector__XXX
 SG_ Throttle_Lifetime_Errs_B : 32|4@1+ (1,0) [0|15] "" Vector__XXX
 SG_ Throttle_Lifetime_Errs_A : 28|4@1+ (1,0) [0|15] "" Vector__XXX
 SG_ DCDC_hiccup_Counter : 24|4@1+ (1,0) [0|15] "" Vector__XXX
 SG_ Power_Stage_Tel : 22|2@1+ (1,0) [0|3] "" Vector__XXX
 SG_ Kill_Switch_Tel : 21|1@1+ (1,0) [0|1] "" Vector__XXX
 SG_ Direction_Tel : 16|2@1+ (1,0) [0|3] "" Vector__XXX
 SG_ Drive_Manoeuvre_Tel : 18|3@1+ (1,0) [0|0] "" Vector__XXX
 SG_ Derating_Tel : 8|8@1+ (1,0) [0|1] "" Vector__XXX
 SG_ Controller_temperature_Tel : 0|8@1+ (1,-40) [-40|215] "°C"  TEL

BO_ 623 BMS_Diagnostics_Data: 8 BMS
 SG_ BMS_Key_ADC_value : 0|1@1+ (1,0) [0|1] "" Vector__XXX

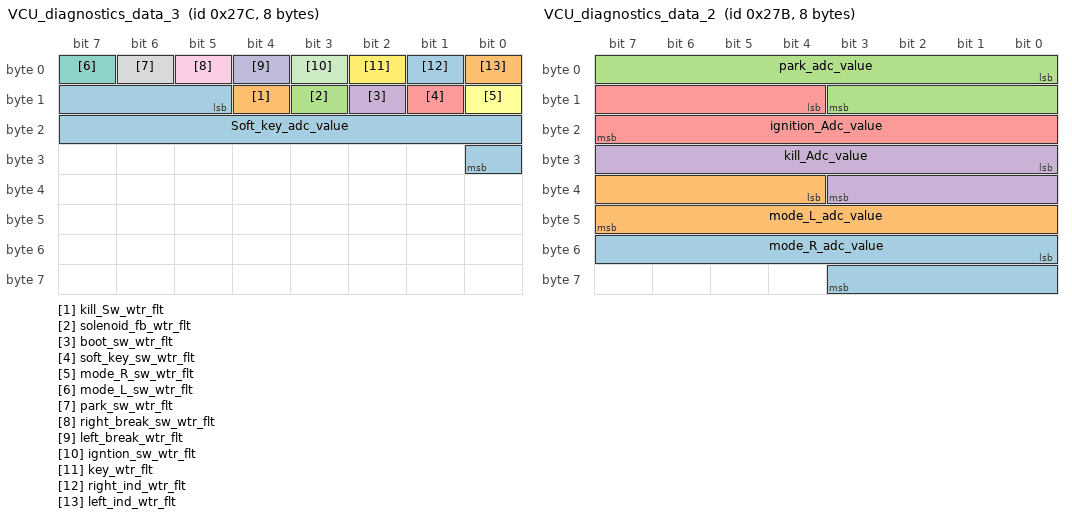
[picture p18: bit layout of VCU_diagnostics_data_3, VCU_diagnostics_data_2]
BO_ 636 VCU_diagnostics_data_3: 8 VCU
 SG_ Soft_key_adc_value : 13|12@1+ (1,0) [0|4095] "" Vector__XXX
 SG_ kill_Sw_wtr_flt : 12|1@1+ (1,0) [0|1] "" Vector__XXX
 SG_ solenoid_fb_wtr_flt : 11|1@1+ (1,0) [0|1] "" Vector__XXX
 SG_ boot_sw_wtr_flt : 10|1@1+ (1,0) [0|1] "" Vector__XXX
 SG_ soft_key_sw_wtr_flt : 9|1@1+ (1,0) [0|1] "" Vector__XXX
 SG_ mode_R_sw_wtr_flt : 8|1@1+ (1,0) [0|1] "" Vector__XXX
 SG_ mode_L_sw_wtr_flt : 7|1@1+ (1,0) [0|1] "" Vector__XXX
 SG_ park_sw_wtr_flt : 6|1@1+ (1,0) [0|1] "" Vector__XXX
 SG_ right_break_sw_wtr_flt : 5|1@1+ (1,0) [0|1] "" Vector__XXX
 SG_ left_break_wtr_flt : 4|1@1+ (1,0) [0|1] "" Vector__XXX
 SG_ igntion_sw_wtr_flt : 3|1@1+ (1,0) [0|1] "" Vector__XXX
 SG_ key_wtr_flt : 2|1@1+ (1,0) [0|1] "" Vector__XXX
 SG_ right_ind_wtr_flt : 1|1@1+ (1,0) [0|1] "" Vector__XXX
 SG_ left_ind_wtr_flt : 0|1@1+ (1,0) [0|1] "" Vector__XXX

BO_ 635 VCU_diagnostics_data_2: 8 VCU
 SG_ mode_R_adc_value : 48|12@1+ (1,0) [0|65535] "" Vector__XXX
 SG_ mode_L_adc_value : 36|12@1+ (1,0) [0|65535] "" Vector__XXX
 SG_ park_adc_value : 0|12@1+ (1,0) [0|4095] "" Vector__XXX
 SG_ kill_Adc_value : 24|12@1+ (1,0) [0|4095] "" Vector__XXX
 SG_ ignition_Adc_value : 12|12@1+ (1,0) [0|65535] "" Vector__XXX

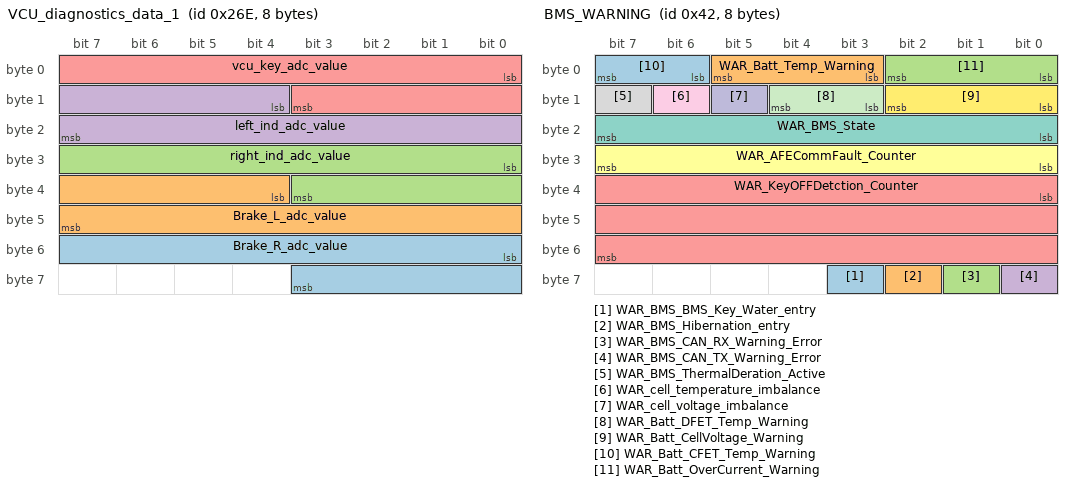
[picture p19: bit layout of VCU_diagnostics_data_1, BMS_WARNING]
BO_ 622 VCU_diagnostics_data_1: 8 VCU
 SG_ Brake_R_adc_value : 48|12@1+ (1,0) [0|4095] "" Vector__XXX
 SG_ Brake_L_adc_value : 36|12@1+ (1,0) [0|4095] "" Vector__XXX
 SG_ right_ind_adc_value : 24|12@1+ (1,0) [0|65535] "" Vector__XXX
 SG_ left_ind_adc_value : 12|12@1+ (1,0) [0|65535] "" Vector__XXX
 SG_ vcu_key_adc_value : 0|12@1+ (1,0) [0|65535] "" Vector__XXX

BO_ 593 Tel_data_5: 8 VCU
 SG_ Charger_HW_error_code_VCU : 16|5@1+ (1,0) [0|31] "" Vector__XXX
 SG_ Hot_n_Cold_Short_Counter_VCU : 0|15@1+ (1,0) [0|32767] "" Vector__XXX

BO_ 72 BMS_Fault_Code: 8 BMS
 SG_ FLT_BMS_Fault_code_2 : 16|8@1+ (1,0) [0|255] "" Vector__XXX
 SG_ FLT_BMS_Fault_code_1 : 8|8@1+ (1,0) [0|255] "" Vector__XXX
 SG_ FLT_BMS_Fault_code_0 : 0|8@1+ (1,0) [0|255] "" Vector__XXX

BO_ 66 BMS_WARNING: 8 BMS
 SG_ WAR_BMS_BMS_Key_Water_entry : 59|1@1+ (1,0) [0|1] "" Vector__XXX
 SG_ WAR_BMS_Hibernation_entry : 58|1@1+ (1,0) [0|1] "" Vector__XXX
 SG_ WAR_BMS_CAN_RX_Warning_Error : 57|1@1+ (1,0) [0|1] "" Vector__XXX
 SG_ WAR_BMS_CAN_TX_Warning_Error : 56|1@1+ (1,0) [0|1] "" Vector__XXX
 SG_ WAR_KeyOFFDetction_Counter : 32|24@1+ (1,0) [0|4294967295] ""  VCU
 SG_ WAR_AFECommFault_Counter : 24|8@1+ (1,0) [0|255] ""  VCU
 SG_ WAR_BMS_State : 16|8@1+ (1,0) [0|255] ""  VCU
 SG_ WAR_BMS_ThermalDeration_Active : 15|1@1+ (1,0) [0|1] ""  VCU
 SG_ WAR_cell_temperature_imbalance : 14|1@1+ (1,0) [0|1] "" Vector__XXX
 SG_ WAR_cell_voltage_imbalance : 13|1@1+ (1,0) [0|1] "" Vector__XXX
 SG_ WAR_Batt_DFET_Temp_Warning : 11|2@1+ (1,0) [0|3] ""  VCU
 SG_ WAR_Batt_CellVoltage_Warning : 8|3@1+ (1,0) [0|7] ""  VCU
 SG_ WAR_Batt_CFET_Temp_Warning : 6|2@1+ (1,0) [0|3] ""  VCU
 SG_ WAR_Batt_Temp_Warning : 3|3@1+ (1,0) [0|7] ""  VCU
 SG_ WAR_Batt_OverCurrent_Warning : 0|3@1+ (1,0) [0|7] ""  VCU

CM_ SG_ 1042 Gradient_Flag "denotes if the algo is detecting a gradient";
BA_DEF_ SG_  "SigType" ENUM  "Default","Range","RangeSigned","ASCII","Discrete","Control","ReferencePGN","DTC","StringDelimiter","StringLength","StringLengthControl","MessageCounter","MessageChecksum";
BA_DEF_ BO_  "GenMsgRequestable" INT 0 1;
BA_DEF_ BO_  "GenMsgSendType" ENUM  "Fixed Periodic","Event","Event Periodic";
BA_DEF_ BO_  "GenMsgCycleTime" INT 0 1000000;
BA_DEF_  "ProtocolType" STRING ;
BA_DEF_  "DBName" STRING ;
BA_DEF_  "BusType" STRING ;
BA_DEF_DEF_  "SigType" "Default";
BA_DEF_DEF_  "GenMsgRequestable" 1;
BA_DEF_DEF_  "GenMsgSendType" "Fixed Periodic";
BA_DEF_DEF_  "GenMsgCycleTime" 0;
BA_DEF_DEF_  "ProtocolType" "CAN Standard";
BA_DEF_DEF_  "DBName" "";
BA_DEF_DEF_  "BusType" "CAN";
BA_ "DBName" "RX1_VehicleGEN2_500K_DBC";
BA_ "DBName" "RX1_VehicleGEN2_500K_DBC";
BA_ "GenMsgCycleTime" BO_ 1799 10000;
BA_ "GenMsgCycleTime" BO_ 628 1000;
BA_ "GenMsgCycleTime" BO_ 615 250;
BA_ "GenMsgCycleTime" BO_ 614 1000;
BA_ "GenMsgCycleTime" BO_ 612 1000;
BA_ "GenMsgCycleTime" BO_ 611 1000;
BA_ "GenMsgCycleTime" BO_ 587 10;
BA_ "GenMsgCycleTime" BO_ 586 10;
BA_ "GenMsgCycleTime" BO_ 584 1000;
BA_ "GenMsgCycleTime" BO_ 1797 10000;
BA_ "GenMsgCycleTime" BO_ 1830 10000;
BA_ "GenMsgCycleTime" BO_ 1829 10000;
BA_ "GenMsgCycleTime" BO_ 1795 10000;
BA_ "GenMsgCycleTime" BO_ 1796 10000;
BA_ "GenMsgCycleTime" BO_ 1828 1000;
BA_ "GenMsgCycleTime" BO_ 1794 10000;
BA_ "GenMsgCycleTime" BO_ 1792 10000;
BA_ "GenMsgCycleTime" BO_ 1827 1000;
BA_ "GenMsgSendType" BO_ 1827 2;
BA_ "GenMsgCycleTime" BO_ 1793 10000;
BA_ "GenMsgSendType" BO_ 1857 1;
BA_ "GenMsgSendType" BO_ 1638 1;
BA_ "GenMsgSendType" BO_ 1877 1;
BA_ "GenMsgCycleTime" BO_ 117 1000;
BA_ "GenMsgCycleTime" BO_ 610 1000;
BA_ "GenMsgCycleTime" BO_ 609 1000;
BA_ "GenMsgCycleTime" BO_ 580 15000;
BA_ "GenMsgCycleTime" BO_ 579 100;
BA_ "GenMsgCycleTime" BO_ 578 100;
BA_ "GenMsgCycleTime" BO_ 573 1000;
BA_ "GenMsgCycleTime" BO_ 572 1000;
BA_ "GenMsgCycleTime" BO_ 571 1000;
BA_ "GenMsgCycleTime" BO_ 570 1000;
BA_ "GenMsgCycleTime" BO_ 569 1000;
BA_ "GenMsgCycleTime" BO_ 568 1000;
BA_ "GenMsgCycleTime" BO_ 567 1000;
BA_ "GenMsgCycleTime" BO_ 566 1000;
BA_ "GenMsgCycleTime" BO_ 565 200;
BA_ "GenMsgCycleTime" BO_ 563 100;
BA_ "GenMsgCycleTime" BO_ 562 100;
BA_ "GenMsgCycleTime" BO_ 561 100;
BA_ "GenMsgCycleTime" BO_ 564 250;
BA_ "GenMsgCycleTime" BO_ 333 250;
BA_ "GenMsgCycleTime" BO_ 332 200;
BA_ "GenMsgCycleTime" BO_ 331 50;
BA_ "GenMsgCycleTime" BO_ 329 200;
BA_ "GenMsgCycleTime" BO_ 327 1000;
BA_ "GenMsgCycleTime" BO_ 326 10;
BA_ "GenMsgCycleTime" BO_ 325 100;
BA_ "GenMsgCycleTime" BO_ 324 10;
BA_ "GenMsgCycleTime" BO_ 323 10;
BA_ "GenMsgCycleTime" BO_ 321 50;
BA_ "GenMsgCycleTime" BO_ 70 50;
BA_ "GenMsgCycleTime" BO_ 69 200;
BA_ "GenMsgCycleTime" BO_ 68 200;
BA_ "GenMsgCycleTime" BO_ 67 200;
BA_ "GenMsgCycleTime" BO_ 65 50;
BA_ "GenMsgCycleTime" BO_ 54 100;
BA_ "GenMsgCycleTime" BO_ 53 200;
BA_ "GenMsgSendType" BO_ 53 2;
BA_ "GenMsgSendType" BO_ 52 1;
BA_ "GenMsgSendType" BO_ 51 1;
BA_ "GenMsgSendType" BO_ 50 1;
BA_ "GenMsgSendType" BO_ 49 1;
BA_ "GenMsgSendType" BO_ 32 1;
BA_ "GenMsgCycleTime" BO_ 629 1000;
BA_ "GenMsgCycleTime" BO_ 1047 200;
BA_ "GenMsgCycleTime" BO_ 1045 200;
BA_ "GenMsgCycleTime" BO_ 1043 100;
BA_ "GenMsgCycleTime" BO_ 1042 100;
BA_ "GenMsgCycleTime" BO_ 1048 200;
BA_ "GenMsgCycleTime" BO_ 336 100;
BA_ "GenMsgCycleTime" BO_ 591 100;
BA_ "GenMsgCycleTime" BO_ 590 100;
BA_ "GenMsgCycleTime" BO_ 330 100;
BA_ "GenMsgCycleTime" BO_ 328 50;
BA_ "GenMsgCycleTime" BO_ 617 100;
BA_ "GenMsgCycleTime" BO_ 322 10;
BA_ "GenMsgCycleTime" BO_ 581 1000;
BA_ "GenMsgCycleTime" BO_ 623 1000;
BA_ "GenMsgCycleTime" BO_ 636 1000;
BA_ "GenMsgCycleTime" BO_ 635 1000;
BA_ "GenMsgCycleTime" BO_ 622 1000;
BA_ "GenMsgCycleTime" BO_ 66 50;
VAL_ 1638 Version_Request 1 "Update Version" 0 "Default" ;
VAL_ 580 VCU_VehicleModeStatus_TelData 6 "Traction disable" 5 "Linphome mode while traction" 4 "Charge" 3 "Traction" 2 "Idle" 1 "Authentication" 0 "Lock" ;
VAL_ 578 Mode_Tel_Data 7 "Reserved" 6 "Reserved" 5 "Reserved" 4 "Reserved" 3 "Rush" 2 "Ride" 1 "Eco" 0 "Reserved" ;
VAL_ 569 Cell_14_BalancingStatus 1 "Balancing" 0 "Not Balancing" ;
VAL_ 569 Cell_13_BalancingStatus 1 "Balancing" 0 "Not Balancing" ;
VAL_ 569 Cell_12_BalancingStatus 1 "Balancing" 0 "Not Balancing" ;
VAL_ 569 Cell_11_BalancingStatus 1 "Balancing" 0 "Not Balancing" ;
VAL_ 569 Cell_10_BalancingStatus 1 "Balancing" 0 "Not Balancing" ;
VAL_ 569 Cell_9_BalancingStatus 1 "Balancing" 0 "Not Balancing" ;
VAL_ 569 Cell_8_BalancingStatus 1 "Balancing" 0 "Not Balancing" ;
VAL_ 569 Cell_7_BalancingStatus 1 "Balancing" 0 "Not Balancing" ;
VAL_ 569 Cell_6_BalancingStatus 1 "Balancing" 0 "Not Balancing" ;
VAL_ 569 Cell_5_BalancingStatus 1 "Balancing" 0 "Not Balancing" ;
VAL_ 569 Cell_4_BalancingStatus 1 "Balancing" 0 "Not Balancing" ;
VAL_ 569 Cell_3_BalancingStatus 1 "Balancing" 0 "Not Balancing" ;
VAL_ 569 Cell_2_BalancingStatus 1 "Balancing" 0 "Not Balancing" ;
VAL_ 569 Cell_1_BalancingStatus 1 "Balancing" 0 "Not Balancing" ;
VAL_ 563 Brightness_control 10 "100% Brightness" 9 "90% Brightness" 8 "80% Brightness" 7 "70% Brightness" 6 "60% Brightness" 5 "50% Brightness" 4 "40% Brightness" 3 "30% Brightness" 2 "20% Brightness" 1 "10% Brightness" 0 "100% Brightness" ;
VAL_ 563 Selected_Trip_Status 1 "Trip2" 0 "Trip1" ;
VAL_ 563 ParkArrowBlink 3 "Top and Bottom Arrow Blink" 2 "Top Arrow Blink" 1 "Bottom Arrow Blink" 0 "No Blink" ;
VAL_ 563 Trip1_Blink 1 "Blinking" 0 "No Blinking" ;
VAL_ 563 Trip2_Blink 1 "Blinking" 0 "No Blinking" ;
VAL_ 563 Reset 7 "Reserved" 6 "Reserved" 5 "Reserved" 4 "Reserved" 3 "Clear Service Icon" 2 "Reset Trip 2" 1 "Reset Trip1" 0 "Default" ;
VAL_ 563 Odo_Reset 1 "Enabled" 0 "Disabled" ;
VAL_ 563 Service_Blink 1 "Blinking" 0 "No Blinking" ;
VAL_ 563 Hibernation 2 "Blink" 1 "Enabled" 0 "Disabled" ;
VAL_ 563 SpeedMode 3 "Rush" 2 "Ride" 1 "Eco" 0 "Default" ;
VAL_ 563 ParkBlink 1 "Blinking" 0 "No Blinking" ;
VAL_ 563 Am_Pm 1 "pm" 0 "am" ;
VAL_ 563 Mode_Blink 1 "Blinking" 0 "No Blinking" ;
VAL_ 563 SOC_Blink 1 "Blinking" 0 "No Blinking" ;
VAL_ 563 Speed_Blink 1 "Blinking" 0 "No Blinking" ;
VAL_ 562 VCU_DisplayMode 9 "Reserved" 8 "Reserved" 7 "Reserved" 6 "Factory Mode" 5 "Charging" 4 "Park Forward" 3 "Park Reverse" 2 "Forward" 1 "Idle" 0 "Sleep" ;
VAL_ 562 ChargerPlugStatus 1 "Connected" 0 "Not Connected" ;
VAL_ 562 SideStandStatus 1 "Up" 0 "Down" ;
VAL_ 562 RegenStatus 1 "Enabled" 0 "Disabled" ;
VAL_ 562 Service_Icon 1 "Enabled" 0 "Disabled" ;
VAL_ 332 STA_TripStatus 1 "Trip2" 0 "Trip1" ;
VAL_ 332 STA_Set_Sleep_SwitchStatus 1 "Pressed" 0 "Not  Pressed" ;
VAL_ 332 Reserved_2 1 "Pressed" 0 "Not  Pressed" ;
VAL_ 332 STA_Adjust_Switch_Status 1 "Pressed" 0 "Not  Pressed" ;
VAL_ 329 Charger_TX 1 "Disable" 0 "Enable" ;
VAL_ 329 Charger_LED_Color 3 "Reserved" 2 "Green" 1 "Red" 0 "Disable" ;
VAL_ 326 LimpHome 1 "Enabled" 0 "Disabled" ;
VAL_ 326 Throttle_takeover 1 "VCU CAN Command throttle%" 0 "Motor Controller HW Throttle%" ;
VAL_ 326 DriveMode_Request 3 "Rush" 2 "Ride" 1 "Eco" 0 "Default" ;
VAL_ 326 Drive_Enable 1 "Enabled" 0 "Disabled" ;
VAL_ 326 Regen_Flag 1 "Enabled" 0 "Disabled" ;
VAL_ 326 park_Mode_Enable 1 "Park Enabled" 0 "Park Disabled" ;
VAL_ 326 Park_Mode_Direction 1 "Forward" 0 "Reverse" ;
VAL_ 326 BMS_MOSFET_Status 1 "Enabled" 0 "Disabled" ;
VAL_ 324 Error_Actions 94 "Kill switch Off" 93 "Kill switch SRO" 83 "Motor stalled " 82 "Throttle SRO" 52 "High motor temperature " 51 "High controller temperature " 97 "Motor control error " 96 "Application parameters fault" 92 "Max. speed exceeded " 90 "Controller logicsupply error " 85 "Throttle channel mismatch " 66 "Contactor coil overcurrent" 56 "Parameter limitation" 54 "Throttle 1 Low Voltage" 53 "Throttle 2 High Voltage" 49 "Corrupted positionsensor cal" 48 "Corrupted Persis Para" 47 "Corrupted Comm parameters \r" 46 "Corrupted throttle calibration" 45 "Corrupted V&I sensor calibration" 44 "Motor temperature sensor" 43 "Controller temperature sensor" 42 "Motor over temperature" 36 "Charging of capacitors failed " 34 "Throttle 1 Low Voltage" 32 "Encoder Fault" 41 "Controller over temperature" 33 "Throttle 1 High Voltage" 31 "Throttle Pedal Cal Error" 26 "Corrupted Application Parameters" 25 "Contactor  Welded" 24 "Contactor Bridge Fault" 21 "Over Current" 18 "Current Sensor Fault" 17 "Sensor Calibration Error V&I" 16 "12V Failure" 15 "5V Failure" 14 "Under Voltage V<32" 13 "Over Voltage V>62" 12 "Low Battery Voltage V<28" 11 "High Battery Voltage V>100" ;
VAL_ 324 Error_Code_4 94 "Kill switch Off" 93 "Kill switch SRO" 83 "Motor stalled " 82 "Throttle SRO" 52 "High motor temperature " 51 "High controller temperature " 97 "Motor control error " 96 "Application parameters fault" 92 "Max. speed exceeded " 90 "Controller logicsupply error " 85 "Throttle channel mismatch " 66 "Contactor coil overcurrent" 56 "Parameter limitation" 54 "Throttle 1 Low Voltage" 53 "Throttle 2 High Voltage" 49 "Corrupted positionsensor cal" 48 "Corrupted Persis Para" 47 "Corrupted Comm parameters \r" 46 "Corrupted throttle calibration" 45 "Corrupted V&I sensor calibration" 44 "Motor temperature sensor" 43 "Controller temperature sensor" 42 "Motor over temperature" 36 "Charging of capacitors failed " 34 "Throttle 1 Low Voltage" 32 "Encoder Fault" 41 "Controller over temperature" 33 "Throttle 1 High Voltage" 31 "Throttle Pedal Cal Error" 26 "Corrupted Application Parameters" 25 "Contactor  Welded" 24 "Contactor Bridge Fault" 21 "Over Current" 18 "Current Sensor Fault" 17 "Sensor Calibration Error V&I" 16 "12V Failure" 15 "5V Failure" 14 "Under Voltage V<32" 13 "Over Voltage V>62" 12 "Low Battery Voltage V<28" 11 "High Battery Voltage V>100" ;
VAL_ 324 Error_Code_2 94 "Kill switch Off" 93 "Kill switch SRO" 83 "Motor stalled " 82 "Throttle SRO" 52 "High motor temperature " 51 "High controller temperature " 97 "Motor control error " 96 "Application parameters fault" 92 "Max. speed exceeded " 90 "Controller logicsupply error " 85 "Throttle channel mismatch " 66 "Contactor coil overcurrent" 56 "Parameter limitation" 54 "Throttle 1 Low Voltage" 53 "Throttle 2 High Voltage" 49 "Corrupted positionsensor cal" 48 "Corrupted Persis Para" 47 "Corrupted Comm parameters \r" 46 "Corrupted throttle calibration" 45 "Corrupted V&I sensor calibration" 44 "Motor temperature sensor" 43 "Controller temperature sensor" 42 "Motor over temperature" 36 "Charging of capacitors failed " 34 "Throttle 1 Low Voltage" 32 "Encoder Fault" 41 "Controller over temperature" 33 "Throttle 1 High Voltage" 31 "Throttle Pedal Cal Error" 26 "Corrupted Application Parameters" 25 "Contactor  Welded" 24 "Contactor Bridge Fault" 21 "Over Current" 18 "Current Sensor Fault" 17 "Sensor Calibration Error V&I" 16 "12V Failure" 15 "5V Failure" 14 "Under Voltage V<32" 13 "Over Voltage V>62" 12 "Low Battery Voltage V<28" 11 "High Battery Voltage V>100" ;
VAL_ 324 Error_Code_1 94 "Kill switch Off" 93 "Kill switch SRO" 83 "Motor stalled " 82 "Throttle SRO" 52 "High motor temperature " 51 "High controller temperature " 97 "Motor control error " 96 "Application parameters fault" 92 "Max. speed exceeded " 90 "Controller logicsupply error " 85 "Throttle channel mismatch " 66 "Contactor coil overcurrent" 56 "Parameter limitation" 54 "Throttle 1 Low Voltage" 53 "Throttle 2 High Voltage" 49 "Corrupted positionsensor cal" 48 "Corrupted Persis Para" 47 "Corrupted Comm parameters \r" 46 "Corrupted throttle calibration" 45 "Corrupted V&I sensor calibration" 44 "Motor temperature sensor" 43 "Controller temperature sensor" 42 "Motor over temperature" 36 "Charging of capacitors failed " 34 "Throttle 1 Low Voltage" 32 "Encoder Fault" 41 "Controller over temperature" 33 "Throttle 1 High Voltage" 31 "Throttle Pedal Cal Error" 26 "Corrupted Application Parameters" 25 "Contactor  Welded" 24 "Contactor Bridge Fault" 21 "Over Current" 18 "Current Sensor Fault" 17 "Sensor Calibration Error V&I" 16 "12V Failure" 15 "5V Failure" 14 "Under Voltage V<32" 13 "Over Voltage V>62" 12 "Low Battery Voltage V<28" 11 "High Battery Voltage V>100" ;
VAL_ 324 Error_Code_0 94 "Kill switch Off" 93 "Kill switch SRO" 83 "Motor stalled " 82 "Throttle SRO" 52 "High motor temperature " 51 "High controller temperature " 97 "Motor control error " 96 "Application parameters fault" 92 "Max. speed exceeded " 90 "Controller logicsupply error " 85 "Throttle channel mismatch " 66 "Contactor coil overcurrent" 56 "Parameter limitation" 54 "Throttle 1 Low Voltage" 53 "Throttle 2 High Voltage" 49 "Corrupted positionsensor cal" 48 "Corrupted Persis Para" 47 "Corrupted Comm parameters \r" 46 "Corrupted throttle calibration" 45 "Corrupted V&I sensor calibration" 44 "Motor temperature sensor" 43 "Controller temperature sensor" 42 "Motor over temperature" 36 "Charging of capacitors failed " 34 "Throttle 1 Low Voltage" 32 "Encoder Fault" 41 "Controller over temperature" 33 "Throttle 1 High Voltage" 31 "Throttle Pedal Cal Error" 26 "Corrupted Application Parameters" 25 "Contactor  Welded" 24 "Contactor Bridge Fault" 21 "Over Current" 18 "Current Sensor Fault" 17 "Sensor Calibration Error V&I" 16 "12V Failure" 15 "5V Failure" 14 "Under Voltage V<32" 13 "Over Voltage V>62" 12 "Low Battery Voltage V<28" 11 "High Battery Voltage V>100" ;
VAL_ 321 STA_BMS_VCU_AuthStatus 3 "Fail" 2 "Pass" 1 "InProgress" 0 "Default" ;
VAL_ 321 STA_CAN_BusOFF_Status 1 "Fault" 0 "No Fault" ;
VAL_ 321 STA_OCC_Latch 1 "Lacth" 0 "Default" ;
VAL_ 321 STA_OCD_Latch 1 "Lacth" 0 "Default" ;
VAL_ 321 STA_BatteryFull 1 "Battery Full" 0 "Default" ;
VAL_ 321 STA_Load_V_Present 1 "DFET On" 0 "DFET Off" ;
VAL_ 321 STA_CFET_Status 1 "CFET On" 0 "CFET Off" ;
VAL_ 321 STA_PPINStatus_BMS 1 "Connected" 0 "Not Connected" ;
VAL_ 321 STA_KeyStatus_BMS 1 "Connected" 0 "Not Connected" ;
VAL_ 321 STA_Precharging_Status 3 "Precharging Failed" 2 "Precharging Successful" 1 "Precharging In-progress" 0 "Default" ;
VAL_ 321 STA_DFET_Status 1 "MDFET_ON" 0 "MDFET_OFF" ;
VAL_ 321 STA_BMS_FaultStatus 1 "Error" 0 "Normal" ;
VAL_ 321 STA_BMS_Status 10 "Reserved" 9 "Reserved" 8 "Reserved" 7 "Charge Recovery Fault" 6 "Discharge Recovery Fault" 5 "Critical Fault" 4 "Hibernate" 3 "Charging" 2 "Discharging" 1 "Precharging" 0 "Sleep" ;
VAL_ 70 FLT_System_Dig_init_FaultCode 30 "FaultBitReadAFEHistoryFaultData" 29 "FAULTBIT_READ_AFE_LIFE_TIME_DATA" 28 "FAULT_BIT_INT_FLASH_WRITE_FAILED" 27 "FAULT_BIT_INT_FLASH_READ_FAILED" 26 "AULT_BIT_ADC_READ" 25 "FAULT_BIT_AFE_READ " 24 "FAULT_BIT_POST_OS_INIT_FAILED" 23 "FAULT_BIT_OS_CREATE_INTRPTS" 22 "FAULT_BIT_OS_CREATE_TASK" 21 "FAULT_BIT_OS_CREATE_QUEUE" 20 "FAULT_BIT_OS_CREATE_SEMPR" 19 "FAULT_BIT_CAN_TX" 18 "FAULT_BIT_INTERNAL_FLASH_INIT" 17 "FAULT_BIT_I2C_CRC_ERROR" 16 "FAULT_BIT_I2C_RX_ERROR" 15 "FAULT_BIT_I2C_TX_ERROR" 14 "FAULT_BIT_I2C_INIT" 13 "FAULT_BIT_ADC_INIT" 12 "FAULT_BIT_TIMER_FTM1" 11 "FAULT_BIT_TIMER_FTM0" 10 "FAULT_BIT_CAN_INIT_1" 9 "FAULT_BIT_GPIO_INIT" 8 "FAULT_BIT_CLOCK_UPDATE" 7 "FAULT_BIT_BOOT_CLOCK_INIT" 6 "FAULT_BIT_RESET_SOFT" 5 "FAULT_BIT_RESET_NRST_EXT" 4 "FAULT_BIT_RESET_ACK_ERR" 3 "FAULT_BIT_RESET_LV_DETECT" 2 "FAULT_BIT_RESET_SJTAG" 1 "FAULT_BIT_RESET_POWER_ON" 0 "FAULT_BIT_RESET_WDG" ;
VAL_ 68 FLT_ECU_Error_Code_4 326 "Cell Under Voltage Fault" 325 "Cell Over Voltage Fault" 322 "BrakeLamp_Fault" 318 "BMS_CANMSG_Timeout" 315 "Battery_Thermal_Runaway_Fault" 314 "BatteryDisSortCircuitFault" 312 "Charging_under_temp" 310 "Discharging_under_temp" 309 " Charging_over_current_fault" 308 "Discharging_over_current_fault" 307 "Charging_over_temp" 306 "Discharging_over_temp" 305 "DFET under temperature" 304 "DFET over temperature" 303 "CFET under temperature" 302 "CFET over temperature" 301 "Fuse_Fault" 203 "BMS_SCD" 142 "Throttle_2_Low_Voltage" 140 "Motor_Control_Error" 139 "Application_parameters_Fault" 137 "Kill_switch_SRO" 136 "Max_speed_exceeded" 135 "Controller_logic_supply_error" 134 "Throttle channel mismatch " 133 "Motor Stalled" 132 "Throttle SRO" 131 "Contactor_Coil_Overcurrent" 130 "Parameter_Limitation" 129 "Throttle_2_High_Voltage" 128 "High Motor Temperature" 127 "High Controller Temperature" 126 "Corrupted_Position_Sensor_Cal" 125 "Corrupted_Persis_Para" 124 "Corrupted_Comm_Parameters" 123 "Corrupted_Throttle_Calibration" 122 "Corrupted V&I Sensor Calibration" 121 "Motor_Temperature_Sensor" 120 "Controller_Temperature_Sensor" 119 "Motor over temperature" 118 "Controller over temperature" 117 "Charging_Of_Capacitors_Failed" 116 "Throttle 1 Low Voltage" 115 "Throttle 1 High Voltage" 114 "Encoder_Fault" 113 "Throttle_Pedal_Cal_Error" 112 "Corrupted_Application_Parameters" 111 "Contactor_Welded" 110 "Contactor_Bridge_Fault" 109 "Over_Current" 108 "Current_Sensor_Fault" 107 "Sensor_Calibration_Error_V&I" 106 "12V_Failure" 105 "5V_Failure" 104 "Under_Voltage" 103 "Over_Voltage" 102 "Low_Battery_Voltage" 101 "High_Battery_Voltage" ;
VAL_ 68 FLT_ECU_Error_Code_3 326 "Cell Under Voltage Fault" 325 "Cell Over Voltage Fault" 322 "BrakeLamp_Fault" 318 "BMS_CANMSG_Timeout" 315 "Battery_Thermal_Runaway_Fault" 314 "BatteryDisSortCircuitFault" 312 "Charging_under_temp" 310 "Discharging_under_temp" 309 " Charging_over_current_fault" 308 "Discharging_over_current_fault" 307 "Charging_over_temp" 306 "Discharging_over_temp" 305 "DFET under temperature" 304 "DFET over temperature" 303 "CFET under temperature" 302 "CFET over temperature" 301 "Fuse_Fault" 203 "BMS_SCD" 142 "Throttle_2_Low_Voltage" 140 "Motor_Control_Error" 139 "Application_parameters_Fault" 137 "Kill_switch_SRO" 136 "Max_speed_exceeded" 135 "Controller_logic_supply_error" 134 "Throttle channel mismatch " 133 "Motor Stalled" 132 "Throttle SRO" 131 "Contactor_Coil_Overcurrent" 130 "Parameter_Limitation" 129 "Throttle_2_High_Voltage" 128 "High Motor Temperature" 127 "High Controller Temperature" 126 "Corrupted_Position_Sensor_Cal" 125 "Corrupted_Persis_Para" 124 "Corrupted_Comm_Parameters" 123 "Corrupted_Throttle_Calibration" 122 "Corrupted V&I Sensor Calibration" 121 "Motor_Temperature_Sensor" 120 "Controller_Temperature_Sensor" 119 "Motor over temperature" 118 "Controller over temperature" 117 "Charging_Of_Capacitors_Failed" 116 "Throttle 1 Low Voltage" 115 "Throttle 1 High Voltage" 114 "Encoder_Fault" 113 "Throttle_Pedal_Cal_Error" 112 "Corrupted_Application_Parameters" 111 "Contactor_Welded" 110 "Contactor_Bridge_Fault" 109 "Over_Current" 108 "Current_Sensor_Fault" 107 "Sensor_Calibration_Error_V&I" 106 "12V_Failure" 105 "5V_Failure" 104 "Under_Voltage" 103 "Over_Voltage" 102 "Low_Battery_Voltage" 101 "High_Battery_Voltage" ;
VAL_ 68 FLT_ECU_Error_Code_2 326 "Cell Under Voltage Fault" 325 "Cell Over Voltage Fault" 322 "BrakeLamp_Fault" 318 "BMS_CANMSG_Timeout" 315 "Battery_Thermal_Runaway_Fault" 314 "BatteryDisSortCircuitFault" 312 "Charging_under_temp" 310 "Discharging_under_temp" 309 " Charging_over_current_fault" 308 "Discharging_over_current_fault" 307 "Charging_over_temp" 306 "Discharging_over_temp" 305 "DFET under temperature" 304 "DFET over temperature" 303 "CFET under temperature" 302 "CFET over temperature" 301 "Fuse_Fault" 203 "BMS_SCD" 142 "Throttle_2_Low_Voltage" 140 "Motor_Control_Error" 139 "Application_parameters_Fault" 137 "Kill_switch_SRO" 136 "Max_speed_exceeded" 135 "Controller_logic_supply_error" 134 "Throttle channel mismatch " 133 "Motor Stalled" 132 "Throttle SRO" 131 "Contactor_Coil_Overcurrent" 130 "Parameter_Limitation" 129 "Throttle_2_High_Voltage" 128 "High Motor Temperature" 127 "High Controller Temperature" 126 "Corrupted_Position_Sensor_Cal" 125 "Corrupted_Persis_Para" 124 "Corrupted_Comm_Parameters" 123 "Corrupted_Throttle_Calibration" 122 "Corrupted V&I Sensor Calibration" 121 "Motor_Temperature_Sensor" 120 "Controller_Temperature_Sensor" 119 "Motor over temperature" 118 "Controller over temperature" 117 "Charging_Of_Capacitors_Failed" 116 "Throttle 1 Low Voltage" 115 "Throttle 1 High Voltage" 114 "Encoder_Fault" 113 "Throttle_Pedal_Cal_Error" 112 "Corrupted_Application_Parameters" 111 "Contactor_Welded" 110 "Contactor_Bridge_Fault" 109 "Over_Current" 108 "Current_Sensor_Fault" 107 "Sensor_Calibration_Error_V&I" 106 "12V_Failure" 105 "5V_Failure" 104 "Under_Voltage" 103 "Over_Voltage" 102 "Low_Battery_Voltage" 101 "High_Battery_Voltage" ;
VAL_ 68 FLT_ECU_Error_Code_1 326 "Cell Under Voltage Fault" 325 "Cell Over Voltage Fault" 322 "BrakeLamp_Fault" 318 "BMS_CANMSG_Timeout" 315 "Battery_Thermal_Runaway_Fault" 314 "BatteryDisSortCircuitFault" 312 "Charging_under_temp" 310 "Discharging_under_temp" 309 " Charging_over_current_fault" 308 "Discharging_over_current_fault" 307 "Charging_over_temp" 306 "Discharging_over_temp" 305 "DFET under temperature" 304 "DFET over temperature" 303 "CFET under temperature" 302 "CFET over temperature" 301 "Fuse_Fault" 203 "BMS_SCD" 142 "Throttle_2_Low_Voltage" 140 "Motor_Control_Error" 139 "Application_parameters_Fault" 137 "Kill_switch_SRO" 136 "Max_speed_exceeded" 135 "Controller_logic_supply_error" 134 "Throttle channel mismatch " 133 "Motor Stalled" 132 "Throttle SRO" 131 "Contactor_Coil_Overcurrent" 130 "Parameter_Limitation" 129 "Throttle_2_High_Voltage" 128 "High Motor Temperature" 127 "High Controller Temperature" 126 "Corrupted_Position_Sensor_Cal" 125 "Corrupted_Persis_Para" 124 "Corrupted_Comm_Parameters" 123 "Corrupted_Throttle_Calibration" 122 "Corrupted V&I Sensor Calibration" 121 "Motor_Temperature_Sensor" 120 "Controller_Temperature_Sensor" 119 "Motor over temperature" 118 "Controller over temperature" 117 "Charging_Of_Capacitors_Failed" 116 "Throttle 1 Low Voltage" 115 "Throttle 1 High Voltage" 114 "Encoder_Fault" 113 "Throttle_Pedal_Cal_Error" 112 "Corrupted_Application_Parameters" 111 "Contactor_Welded" 110 "Contactor_Bridge_Fault" 109 "Over_Current" 108 "Current_Sensor_Fault" 107 "Sensor_Calibration_Error_V&I" 106 "12V_Failure" 105 "5V_Failure" 104 "Under_Voltage" 103 "Over_Voltage" 102 "Low_Battery_Voltage" 101 "High_Battery_Voltage" ;
VAL_ 68 FLT_ECU_Error_Code_0 326 "Cell Under Voltage Fault" 325 "Cell Over Voltage Fault" 322 "BrakeLamp_Fault" 318 "BMS_CANMSG_Timeout" 315 "Battery_Thermal_Runaway_Fault" 314 "BatteryDisSortCircuitFault" 312 "Charging_under_temp" 310 "Discharging_under_temp" 309 " Charging_over_current_fault" 308 "Discharging_over_current_fault" 307 "Charging_over_temp" 306 "Discharging_over_temp" 305 "DFET under temperature" 304 "DFET over temperature" 303 "CFET under temperature" 302 "CFET over temperature" 301 "Fuse_Fault" 203 "BMS_SCD" 142 "Throttle_2_Low_Voltage" 140 "Motor_Control_Error" 139 "Application_parameters_Fault" 137 "Kill_switch_SRO" 136 "Max_speed_exceeded" 135 "Controller_logic_supply_error" 134 "Throttle channel mismatch " 133 "Motor Stalled" 132 "Throttle SRO" 131 "Contactor_Coil_Overcurrent" 130 "Parameter_Limitation" 129 "Throttle_2_High_Voltage" 128 "High Motor Temperature" 127 "High Controller Temperature" 126 "Corrupted_Position_Sensor_Cal" 125 "Corrupted_Persis_Para" 124 "Corrupted_Comm_Parameters" 123 "Corrupted_Throttle_Calibration" 122 "Corrupted V&I Sensor Calibration" 121 "Motor_Temperature_Sensor" 120 "Controller_Temperature_Sensor" 119 "Motor over temperature" 118 "Controller over temperature" 117 "Charging_Of_Capacitors_Failed" 116 "Throttle 1 Low Voltage" 115 "Throttle 1 High Voltage" 114 "Encoder_Fault" 113 "Throttle_Pedal_Cal_Error" 112 "Corrupted_Application_Parameters" 111 "Contactor_Welded" 110 "Contactor_Bridge_Fault" 109 "Over_Current" 108 "Current_Sensor_Fault" 107 "Sensor_Calibration_Error_V&I" 106 "12V_Failure" 105 "5V_Failure" 104 "Under_Voltage" 103 "Over_Voltage" 102 "Low_Battery_Voltage" 101 "High_Battery_Voltage" ;
VAL_ 67 FLT_CAN_H_G_or_L_VCC 1 "Fault" 0 "No Fault" ;
VAL_ 67 FLT_Supply3v3_Fault 1 "Fault" 0 "No Fault" ;
VAL_ 67 FLT_DRL_FaultFlag 1 "Fault" 0 "No Fault" ;
VAL_ 67 FLT_HighBeam_FaultFlag 1 "Fault" 0 "No Fault" ;
VAL_ 67 FLT_BrakeLamp_Fault 1 "Fault" 0 "No Fault" ;
VAL_ 67 FLT_VCU_BMS_AuthFault 1 "Auth Fault" 0 "No Auth Fault" ;
VAL_ 67 FLT_BMS_PPin_Error 1 "Fault" 0 "No Fault" ;
VAL_ 67 FLT_BMS_CANMsg_Timeout 1 "Fault" 0 "No Fault" ;
VAL_ 67 FLT_Charger_CANMsg_Timeout 1 "Fault" 0 "No Fault" ;
VAL_ 67 FLT_TEL_CANMsg_Timeout 1 "Fault" 0 "No Fault" ;
VAL_ 67 FLT_Display_CANMsg_Timeout 1 "Fault" 0 "No Fault" ;
VAL_ 67 FLT_MCU_CANMsg_Timeout 1 "Fault" 0 "No Fault" ;
VAL_ 67 FLT_BMS_KeyError 1 "Fault" 0 "No Fault" ;
VAL_ 65 FLT_MOSFET_Failure 1 "Fault" 0 "No Fault" ;
VAL_ 65 FLT_Cell_upnormalVoltage 2 "UP_Normal_Min_Voltage_Fault" 1 "UP_Normal_Max_Voltage_Fault" 0 "NO_error" ;
VAL_ 65 FLT_BattChargingTempFault 4 "Reserved" 3 "Reserved" 2 "Charging Under Temperature" 1 "Charging Over Temperature" 0 "No Fault" ;
VAL_ 65 FLT_VCU_PPIn_Error 1 "Fault" 0 "No Fault" ;
VAL_ 65 FLT_BMS_ChargerVoltSenseFault 1 "Fault" 0 "No Fault" ;
VAL_ 65 FLT_BattDFET_TempFault 3 "Reserved" 2 "DFET Under Temperature" 1 "DFET Over Temperature" 0 "No Fault" ;
VAL_ 65 FLT_VCU_KeyError 1 "Fault" 0 "No Fault" ;
VAL_ 65 FLT_BattCFET_TempFault 3 "Reserved" 2 "CFET Uder Temperature" 1 "CFET Over Temperature" 0 "No Fault" ;
VAL_ 65 FLT_VCU_CANMsgTimeout 1 "Fault" 0 "No Fault" ;
VAL_ 65 FLT_AFE_CommFault 1 "Fault" 0 "No Fault" ;
VAL_ 65 FLT_CellVoltageFault 3 "Reserved" 2 "Cell Under Votage Fault" 1 "Cell Over Voltage Fault" 0 "No Fault" ;
VAL_ 65 FLT_BattVoltageFault 3 "Reserved" 2 "Pack Under Voltage Fault" 1 "Pack Over Voltage Fault" 0 "No Fault" ;
VAL_ 65 FLT_CellVoltageMissmatch 1 "Fault" 0 "No Fault" ;
VAL_ 65 FLT_BattDischTempFault 4 "Charging Under Temperature" 3 "Discharging Under Temperature" 2 "Charging Over Temperature" 1 "Discharging Over Temperature" 0 "No Fault" ;
VAL_ 65 FLT_BatteryCurrentFault 3 "RESERVED" 2 " CHARGING_OVER_CURRENT_FAULT" 1 "DISCHARGING_OVER_CURRENT_FAULT" 0 "NO_CURRENT_FAULT" ;
VAL_ 52 Calibration_Ack_Status 171 "Current Mode" 170 "Voltage Mode" 17 "Second Voltage point read" 3 "FinalCurrentPointReadCalibrated" 2 "Current point read" 1 "First Voltage point read" ;
VAL_ 330 StatusofChargerHWError 1 "Error" 0 "Normal" ;
VAL_ 330 StatusofChargerTempError 1 "Error" 0 "Normal" ;
VAL_ 330 StatusofChargerInputError 1 "Error" 0 "Normal" ;
VAL_ 330 StatusofChargerBatError 1 "Error" 0 "Normal" ;
VAL_ 330 StatusofChargerCOMError 1 "Error" 0 "Normal" ;
VAL_ 328 STA_Right_Mode_Switch_status 1 "Pressed" 0 "Not  Pressed" ;
VAL_ 328 STA_Left_Mode_Switch_status 1 "Pressed" 0 "Not  Pressed" ;
VAL_ 328 STA_Charging_Enable 1 "Enabled" 0 "Disabled" ;
VAL_ 328 STA_Error_State 2 "Permanenet_Fault" 1 "Temporary_Fault" 0 "No Fault" ;
VAL_ 328 STA_Boot_Status 1 "Boot_opean" 0 "Boot_locked" ;
VAL_ 328 STA_Solenoid_FeedbackStatus 1 "solenoid latched" 0 "solenoid unlatched" ;
VAL_ 328 STA_Buzzer_Status 1 "Enabled" 0 "Disabled" ;
VAL_ 328 STA_Traction_Mode_Status 7 "Reserved" 6 "Reserved" 5 "Reserved" 4 "Reserved" 3 "Limphome" 2 "Park Reverse" 1 "Foward" 0 "Default" ;
VAL_ 328 STA_VCU_LED_BlinkStatus 1 "Enabled" 0 "Disabled" ;
VAL_ 328 STA_KeyConnectionStatus_VCU 1 "Connected" 0 "Not Connected" ;
VAL_ 328 STA_VehicleModeStatus 6 "Traction disable" 5 "Linphome mode while traction" 4 "Charge" 3 "Traction" 2 "Idle" 1 "Authentication" 0 "Lock" ;
VAL_ 328 STA_PPINStatus_VCU 1 "Connected" 0 "Not Connected" ;
VAL_ 328 STA_RTD_Flag 1 "Enabled" 0 "Disabled" ;
VAL_ 328 STA_DisplaySupplyStatus 1 "Enabled" 0 "Disabled" ;
VAL_ 328 STA_KillSwitchStatus 1 "kill Switch Off" 0 "Kill Switch On" ;
VAL_ 328 STA_SideStandStatus 1 "Up" 0 "Down" ;
VAL_ 328 STA_BrakeStatus 1 "Pressed" 0 "Not  Pressed" ;
VAL_ 328 STA_IndicatorSwitchStatus 1 "Pressed" 0 "Not  Pressed" ;
VAL_ 328 STA_Park_Switch 1 "Pressed" 0 "Not  Pressed" ;
VAL_ 328 STA_IgnitionSwitchStatus 1 "Pressed" 0 "Not  Pressed" ;
VAL_ 322 LimpHome_Ack 1 "Enabled" 0 "Disabled" ;
VAL_ 322 Deratings 1 "Enabled" 0 "Disabled" ;
VAL_ 322 Drive_Manoeuvre 4 "Acceleration Backward" 3 "Direction Transition" 2 "Service Braking " 1 "Neutral braking" 0 "Accelartion Forward  " ;
VAL_ 322 Direction 3 "Reserved" 2 "Reverse" 1 "Forward" 0 "Neutral" ;
VAL_ 322 Kill_Switch 1 "Kill Switch Off" 0 "Kill Switch On" ;
VAL_ 322 Power_Stage 3 "Not Used" 2 "On" 1 "Active Short" 0 "Off" ;
VAL_ 322 DriveMode_Ack 7 "Reserved" 6 "Reserved" 5 "Reserved" 4 "Reserved" 3 "Rush" 2 "Ride" 1 "Eco" 0 "Reserved" ;
VAL_ 581 Power_Stage_Tel 3 "Not Used" 2 "On" 1 "Active Short" 0 "Off" ;
VAL_ 581 Kill_Switch_Tel 1 "Kill Switch Off" 0 "Kill Switch On" ;
VAL_ 581 Direction_Tel 3 "Reserved" 2 "Reverse" 1 "Forward" 0 "Neutral" ;
VAL_ 581 Drive_Manoeuvre_Tel 4 "Acceleration Backward" 3 "Direction Transition" 2 "Service Braking " 1 "Neutral braking" 0 "Accelartion Forward  " ;
